VERSION ""

NS_ :

BS_:

BU_: INV BMS VCU

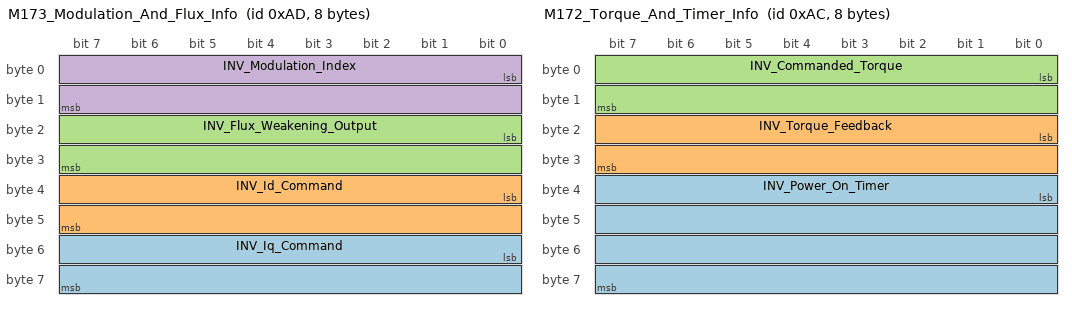
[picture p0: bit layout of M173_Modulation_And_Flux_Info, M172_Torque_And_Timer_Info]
BO_ 173 M173_Modulation_And_Flux_Info: 8 INV
 SG_ INV_Iq_Command : 48|16@1- (0.1,0) [-3276.8|3276.7] "current:A" Vector__XXX
 SG_ INV_Id_Command : 32|16@1- (0.1,0) [-3276.8|3276.7] "current:A" Vector__XXX
 SG_ INV_Flux_Weakening_Output : 16|16@1- (0.1,0) [-3276.8|3276.7] "current:A" Vector__XXX
 SG_ INV_Modulation_Index : 0|16@1- (0.0001,0) [-3.2768|3.2767] "" Vector__XXX

BO_ 172 M172_Torque_And_Timer_Info: 8 INV
 SG_ INV_Power_On_Timer : 32|32@1+ (0.003,0) [0|12884800] "time:second" Vector__XXX
 SG_ INV_Torque_Feedback : 16|16@1- (0.1,0) [-3276.8|3276.7] "torque:N.m" Vector__XXX
 SG_ INV_Commanded_Torque : 0|16@1- (0.1,0) [-3276.8|3276.7] "torque:N.m" Vector__XXX

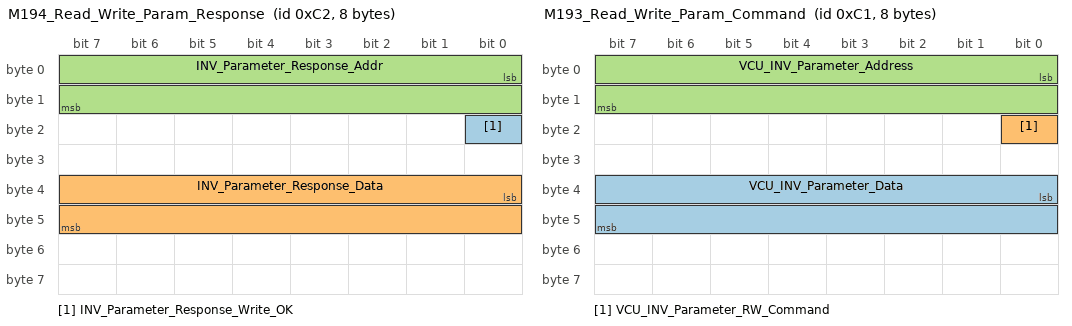
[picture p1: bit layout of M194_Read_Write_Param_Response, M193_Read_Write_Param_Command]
BO_ 194 M194_Read_Write_Param_Response: 8 INV
 SG_ INV_Parameter_Response_Write_OK : 16|1@1+ (1,0) [0|1] "" Vector__XXX
 SG_ INV_Parameter_Response_Data : 32|16@1- (1,0) [-32768|32767] "" Vector__XXX
 SG_ INV_Parameter_Response_Addr : 0|16@1+ (1,0) [0|65535] "" Vector__XXX

BO_ 193 M193_Read_Write_Param_Command: 8 VCU
 SG_ VCU_INV_Parameter_Data : 32|16@1- (1,0) [-32768|32767] "" Vector__XXX
 SG_ VCU_INV_Parameter_RW_Command : 16|1@1+ (1,0) [0|1] "" Vector__XXX
 SG_ VCU_INV_Parameter_Address : 0|16@1+ (1,0) [0|65535] "" Vector__XXX

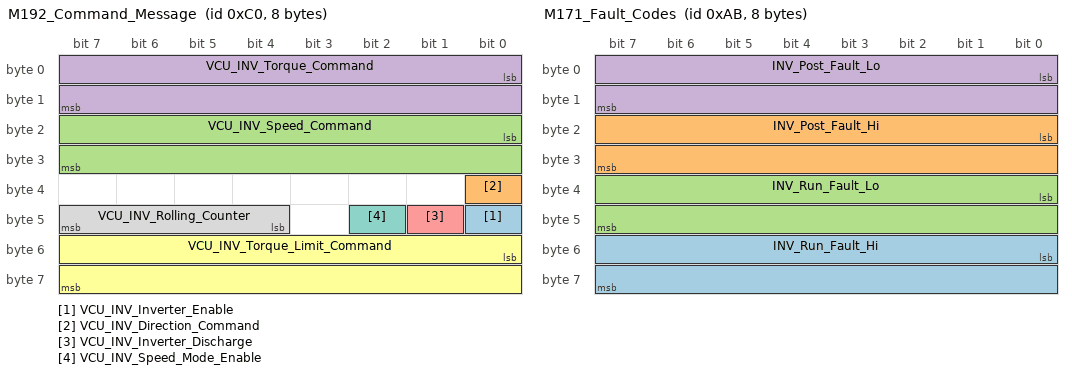
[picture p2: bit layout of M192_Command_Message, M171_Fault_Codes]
BO_ 192 M192_Command_Message: 8 VCU
 SG_ VCU_INV_Inverter_Enable : 40|1@1+ (1,0) [0|1] "" Vector__XXX
 SG_ VCU_INV_Direction_Command : 32|1@1+ (1,0) [0|1] "" Vector__XXX
 SG_ VCU_INV_Speed_Command : 16|16@1- (1,0) [-32768|32767] "angular_speed:rpm" Vector__XXX
 SG_ VCU_INV_Torque_Command : 0|16@1- (0.1,0) [-3276.8|3276.7] "torque:N.m" Vector__XXX
 SG_ VCU_INV_Inverter_Discharge : 41|1@1+ (1,0) [0|1] "" Vector__XXX
 SG_ VCU_INV_Torque_Limit_Command : 48|16@1- (0.1,0) [-3276.8|3276.7] "torque:N.m" Vector__XXX
 SG_ VCU_INV_Speed_Mode_Enable : 42|1@1+ (1,0) [0|1] "" Vector__XXX
 SG_ VCU_INV_Rolling_Counter : 44|4@1+ (1,0) [0|15] "" Vector__XXX

BO_ 171 M171_Fault_Codes: 8 INV
 SG_ INV_Run_Fault_Hi : 48|16@1+ (1,0) [0|65535] "" Vector__XXX
 SG_ INV_Post_Fault_Hi : 16|16@1+ (1,0) [0|65535] "" Vector__XXX
 SG_ INV_Run_Fault_Lo : 32|16@1+ (1,0) [0|65535] "" Vector__XXX
 SG_ INV_Post_Fault_Lo : 0|16@1+ (1,0) [0|65535] "" Vector__XXX

BO_ 170 M170_Internal_States: 8 INV
 SG_ INV_Direction_Command : 56|1@1+ (1,0) [0|1] "" Vector__XXX
 SG_ INV_Inverter_Enable_State : 48|1@1+ (1,0) [0|1] "" Vector__XXX
 SG_ INV_Relay_3_Status : 26|1@1+ (1,0) [0|1] "" Vector__XXX
 SG_ INV_Relay_4_Status : 27|1@1+ (1,0) [0|1] "" Vector__XXX
 SG_ INV_Relay_2_Status : 25|1@1+ (1,0) [0|1] "" Vector__XXX
 SG_ INV_Inverter_Run_Mode : 32|1@1+ (1,0) [0|1] "" Vector__XXX
 SG_ INV_Inverter_Command_Mode : 40|1@1+ (1,0) [0|1] "" Vector__XXX
 SG_ INV_Relay_1_Status : 24|1@1+ (1,0) [0|1] "" Vector__XXX
 SG_ INV_Inverter_State : 16|8@1+ (1,0) [0|255] "" Vector__XXX
 SG_ INV_VSM_State : 0|8@1+ (1,0) [0|15] "" Vector__XXX
 SG_ INV_Inverter_Enable_Lockout : 55|1@1+ (1,0) [0|1] "" Vector__XXX
 SG_ INV_Inverter_Discharge_State : 37|3@1+ (1,0) [0|7] "" Vector__XXX
 SG_ INV_Relay_5_Status : 28|1@1+ (1,0) [0|1] "" Vector__XXX
 SG_ INV_Relay_6_Status : 29|1@1+ (1,0) [0|1] "" Vector__XXX
 SG_ INV_BMS_Active : 57|1@1+ (1,0) [0|1] "" Vector__XXX
 SG_ INV_BMS_Torque_Limiting : 58|1@1+ (1,0) [0|1] "" Vector__XXX
 SG_ INV_PWM_Frequency : 8|8@1+ (1,0) [0|255] "" Vector__XXX
 SG_ INV_Limit_Max_Speed : 59|1@1+ (1,0) [0|1] "" Vector__XXX
 SG_ INV_Limit_Hot_Spot : 60|1@1+ (1,0) [0|1] "" Vector__XXX
 SG_ INV_Low_Speed_Limiting : 61|1@1+ (1,0) [0|1] "" Vector__XXX
 SG_ INV_Rolling_Counter : 44|4@1+ (1,0) [0|15] "" Vector__XXX
 SG_ INV_Limit_Coolant_Derating : 62|1@1+ (1,0) [0|1] "" Vector__XXX
 SG_ INV_Self_Sensing_Assist_Enable : 33|1@1+ (1,0) [0|1] "" Vector__XXX
 SG_ INV_Limit_Stall_Burst_Model : 63|1@1+ (1,0) [0|1] "" Vector__XXX
 SG_ INV_Burst_Model_Mode : 49|1@1+ (1,0) [0|1] "" Vector__XXX
 SG_ INV_Key_Switch_Start_Status : 54|1@1+ (1,0) [0|1] "" Vector__XXX

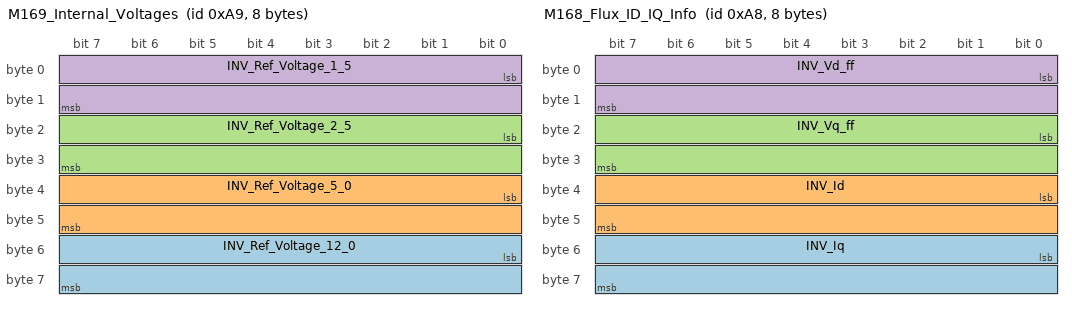
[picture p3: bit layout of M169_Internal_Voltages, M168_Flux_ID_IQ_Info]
BO_ 169 M169_Internal_Voltages: 8 INV
 SG_ INV_Ref_Voltage_12_0 : 48|16@1- (0.01,0) [-327.68|327.67] "voltage:V" Vector__XXX
 SG_ INV_Ref_Voltage_5_0 : 32|16@1- (0.01,0) [-327.68|327.67] "voltage:V" Vector__XXX
 SG_ INV_Ref_Voltage_2_5 : 16|16@1- (0.01,0) [-327.68|327.67] "voltage:V" Vector__XXX
 SG_ INV_Ref_Voltage_1_5 : 0|16@1- (0.01,0) [-327.68|327.67] "voltage:V" Vector__XXX

BO_ 168 M168_Flux_ID_IQ_Info: 8 INV
 SG_ INV_Iq : 48|16@1- (0.1,0) [-3276.8|3276.7] "current:A" Vector__XXX
 SG_ INV_Id : 32|16@1- (0.1,0) [-3276.8|3276.7] "current:A" Vector__XXX
 SG_ INV_Vq_ff : 16|16@1- (0.1,0) [-3276.7|3276.7] "voltage:V" Vector__XXX
 SG_ INV_Vd_ff : 0|16@1- (0.1,0) [-3276.7|3276.7] "voltage:V" Vector__XXX

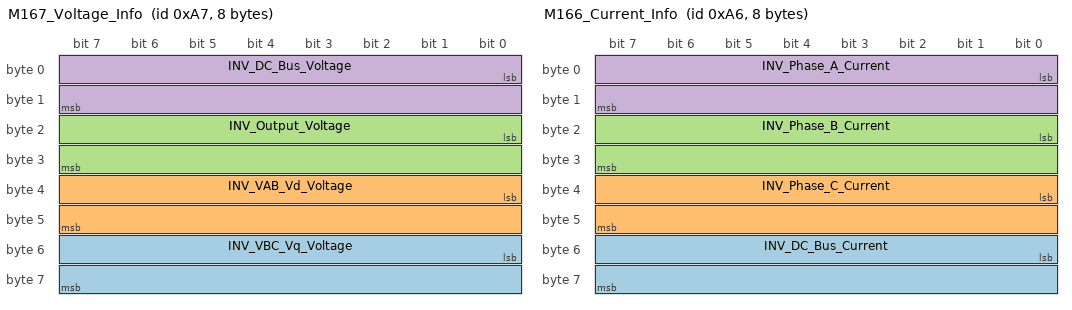
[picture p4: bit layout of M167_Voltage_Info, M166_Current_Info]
BO_ 167 M167_Voltage_Info: 8 INV
 SG_ INV_VBC_Vq_Voltage : 48|16@1- (0.1,0) [-3276.8|3276.7] "voltage:V" Vector__XXX
 SG_ INV_VAB_Vd_Voltage : 32|16@1- (0.1,0) [-3276.8|3276.7] "voltage:V" Vector__XXX
 SG_ INV_Output_Voltage : 16|16@1- (0.1,0) [-3276.8|3276.7] "voltage:V" Vector__XXX
 SG_ INV_DC_Bus_Voltage : 0|16@1- (0.1,0) [-3276.8|3276.7] "voltage:V" Vector__XXX

BO_ 166 M166_Current_Info: 8 INV
 SG_ INV_DC_Bus_Current : 48|16@1- (0.1,0) [-3276.8|3276.7] "current:A" Vector__XXX
 SG_ INV_Phase_C_Current : 32|16@1- (0.1,0) [-3276.8|3276.7] "current:A" Vector__XXX
 SG_ INV_Phase_B_Current : 16|16@1- (0.1,0) [-3276.8|3276.7] "current:A" Vector__XXX
 SG_ INV_Phase_A_Current : 0|16@1- (0.1,0) [-3276.8|3276.7] "current:A" Vector__XXX

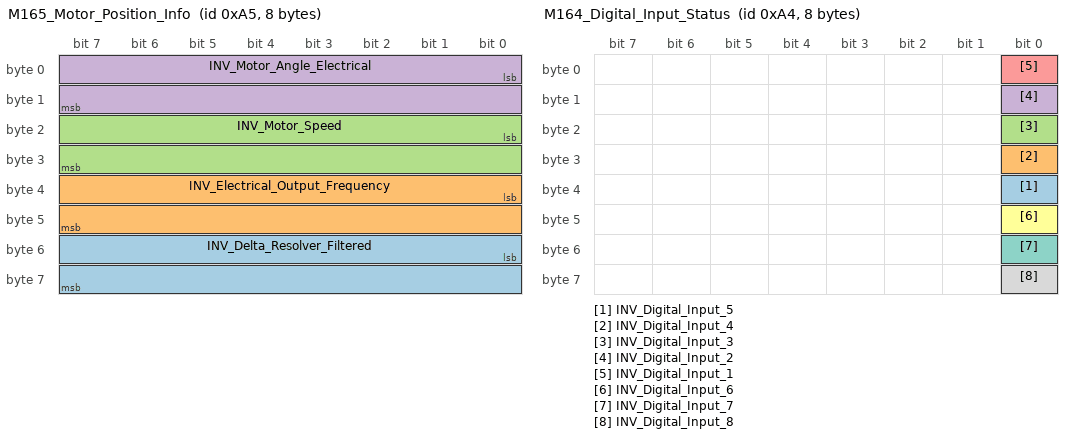
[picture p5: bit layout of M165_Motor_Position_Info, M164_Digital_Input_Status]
BO_ 165 M165_Motor_Position_Info: 8 INV
 SG_ INV_Delta_Resolver_Filtered : 48|16@1- (0.1,0) [-3276.8|3276.7] "angle:deg" Vector__XXX
 SG_ INV_Electrical_Output_Frequency : 32|16@1- (0.1,0) [-3276.8|3276.7] "frequency:Hz" Vector__XXX
 SG_ INV_Motor_Speed : 16|16@1- (1,0) [-32768|32767] "angular_speed:rpm" Vector__XXX
 SG_ INV_Motor_Angle_Electrical : 0|16@1+ (0.1,0) [0|6553.5] "angle:deg" Vector__XXX

BO_ 164 M164_Digital_Input_Status: 8 INV
 SG_ INV_Digital_Input_5 : 32|1@1+ (1,0) [0|1] "" Vector__XXX
 SG_ INV_Digital_Input_4 : 24|1@1+ (1,0) [0|1] "" Vector__XXX
 SG_ INV_Digital_Input_3 : 16|1@1+ (1,0) [0|1] "" Vector__XXX
 SG_ INV_Digital_Input_2 : 8|1@1+ (1,0) [0|1] "" Vector__XXX
 SG_ INV_Digital_Input_1 : 0|1@1+ (1,0) [0|1] "" Vector__XXX
 SG_ INV_Digital_Input_6 : 40|1@1+ (1,0) [0|1] "" Vector__XXX
 SG_ INV_Digital_Input_7 : 48|1@1+ (1,0) [0|1] "" Vector__XXX
 SG_ INV_Digital_Input_8 : 56|1@1+ (1,0) [0|1] "" Vector__XXX

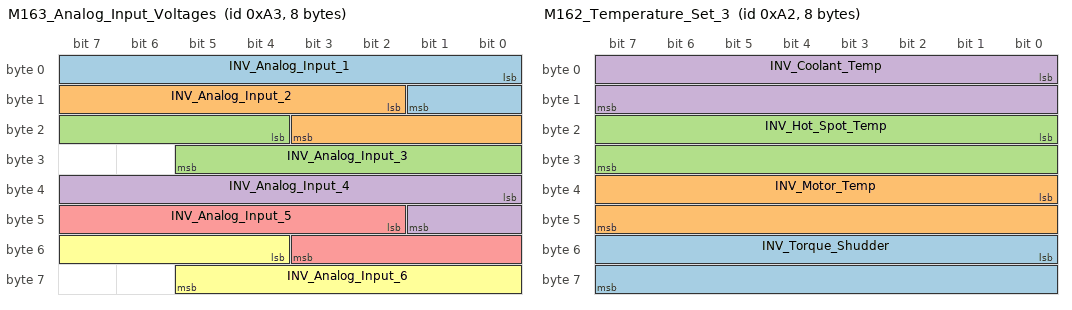
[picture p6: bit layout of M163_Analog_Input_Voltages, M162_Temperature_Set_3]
BO_ 163 M163_Analog_Input_Voltages: 8 INV
 SG_ INV_Analog_Input_1 : 0|10@1+ (0.01,0) [0|10.23] "voltage:V" Vector__XXX
 SG_ INV_Analog_Input_2 : 10|10@1+ (0.01,0) [0|10.23] "voltage:V" Vector__XXX
 SG_ INV_Analog_Input_3 : 20|10@1+ (0.01,0) [0|10.23] "voltage:V" Vector__XXX
 SG_ INV_Analog_Input_4 : 32|10@1+ (0.01,0) [0|10.23] "voltage:V" Vector__XXX
 SG_ INV_Analog_Input_5 : 42|10@1+ (0.01,0) [0|10.23] "voltage:V" Vector__XXX
 SG_ INV_Analog_Input_6 : 52|10@1+ (0.01,0) [0|10.23] "voltage:V" Vector__XXX

BO_ 162 M162_Temperature_Set_3: 8 INV
 SG_ INV_Torque_Shudder : 48|16@1- (0.1,0) [-3276.8|3276.7] "torque:N.m" Vector__XXX
 SG_ INV_Motor_Temp : 32|16@1- (0.1,0) [-3276.8|3276.7] "temperature:C" Vector__XXX
 SG_ INV_Hot_Spot_Temp : 16|16@1- (0.1,0) [-3276.8|3276.7] "temperature:C" Vector__XXX
 SG_ INV_Coolant_Temp : 0|16@1- (0.1,0) [-3276.8|3276.7] "temperature:C" Vector__XXX

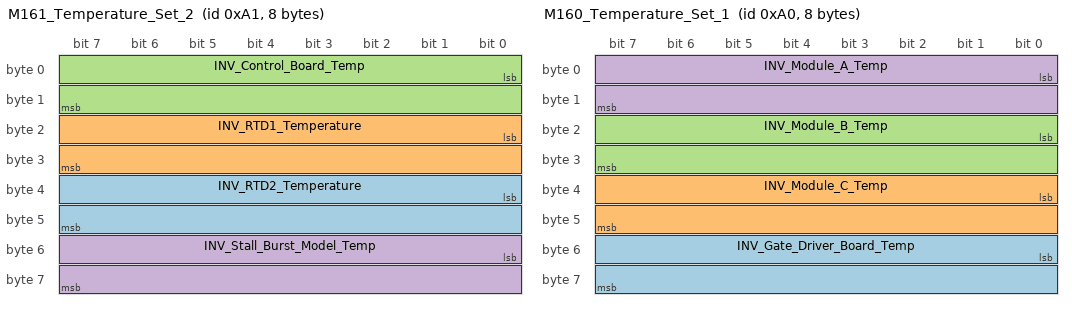
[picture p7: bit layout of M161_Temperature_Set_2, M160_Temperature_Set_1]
BO_ 161 M161_Temperature_Set_2: 8 INV
 SG_ INV_RTD2_Temperature : 32|16@1- (0.1,0) [-3276.8|3276.7] "temperature:C" Vector__XXX
 SG_ INV_RTD1_Temperature : 16|16@1- (0.1,0) [-3276.8|3276.7] "temperature:C" Vector__XXX
 SG_ INV_Control_Board_Temp : 0|16@1- (0.1,0) [-3276.8|3276.7] "temperature:C" Vector__XXX
 SG_ INV_Stall_Burst_Model_Temp : 48|16@1- (0.1,0) [-3276.8|3276.7] "temperature:C" Vector__XXX

BO_ 160 M160_Temperature_Set_1: 8 INV
 SG_ INV_Gate_Driver_Board_Temp : 48|16@1- (0.1,0) [-3276.8|3276.7] "temperature:C" Vector__XXX
 SG_ INV_Module_C_Temp : 32|16@1- (0.1,0) [-3276.8|3276.7] "temperature:C" Vector__XXX
 SG_ INV_Module_B_Temp : 16|16@1- (0.1,0) [-3276.8|3276.7] "temperature:C" Vector__XXX
 SG_ INV_Module_A_Temp : 0|16@1- (0.1,0) [-3276.8|3276.7] "temperature:C" Vector__XXX

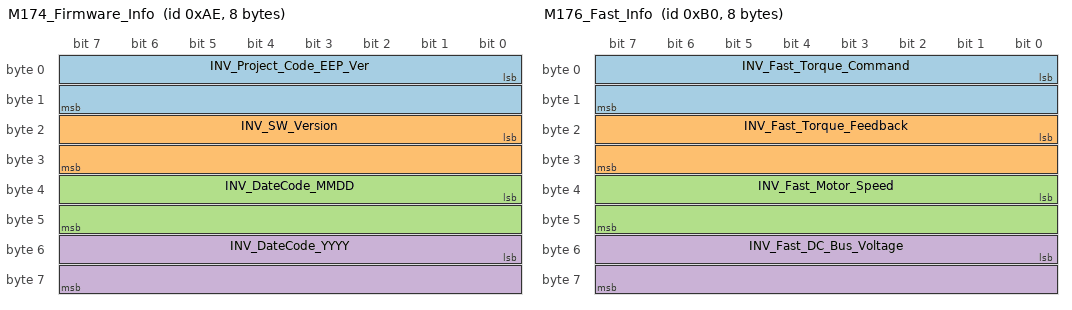
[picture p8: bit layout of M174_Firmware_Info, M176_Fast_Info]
BO_ 174 M174_Firmware_Info: 8 INV
 SG_ INV_Project_Code_EEP_Ver : 0|16@1+ (1,0) [0|65535] "" Vector__XXX
 SG_ INV_SW_Version : 16|16@1+ (1,0) [0|65535] "" Vector__XXX
 SG_ INV_DateCode_MMDD : 32|16@1+ (1,0) [0|65535] "" Vector__XXX
 SG_ INV_DateCode_YYYY : 48|16@1+ (1,0) [0|65535] "" Vector__XXX

BO_ 175 M175_Diag_Data_Message: 8 INV
 SG_ INV_Diag_Record : 0|8@1+ (1,0) [0|160] "" Vector__XXX
 SG_ INV_Diag_Segment M : 8|8@1+ (1,0) [0|5] "" Vector__XXX
 SG_ INV_Diag_Gamma_Resolver m0 : 16|16@1- (0.1,0) [0|360] "angle:deg" Vector__XXX
 SG_ INV_Diag_Gamma_Observer m0 : 32|16@1- (0.1,0) [0|360] "angle:deg" Vector__XXX
 SG_ INV_Diag_Sin_Used m0 : 48|16@1- (1,0) [-5|5] "voltage:V" Vector__XXX
 SG_ INV_Diag_Cos_Used m1 : 16|16@1- (1,0) [-5|5] "voltage:V" Vector__XXX
 SG_ INV_Diag_Ia m1 : 32|16@1- (0.1,0) [-2000|2000] "current:A" Vector__XXX
 SG_ INV_Diag_Ib m1 : 48|16@1- (0.1,0) [-2000|2000] "current:A" Vector__XXX
 SG_ INV_Diag_Ic m2 : 16|16@1- (0.1,0) [-2000|2000] "current:A" Vector__XXX
 SG_ INV_Diag_Vdc m2 : 32|16@1- (0.1,0) [0|1000] "voltage:V" Vector__XXX
 SG_ INV_Diag_Iq_cmd m2 : 48|16@1- (0.1,0) [-2000|2000] "current:A" Vector__XXX
 SG_ INV_Diag_Id_cmd m3 : 16|16@1- (0.1,0) [-2000|2000] "current:A" Vector__XXX
 SG_ INV_Diag_Mod_Index m3 : 32|16@1- (0.0001,0) [0|2] "" Vector__XXX
 SG_ INV_Diag_FW_Output m3 : 48|16@1- (0.1,0) [-2000|2000] "current:A" Vector__XXX
 SG_ INV_Diag_Vq_Cmd m4 : 16|16@1- (0.1,0) [-1000|1000] "voltage:V" Vector__XXX
 SG_ INV_Diag_Vd_Cmd m4 : 32|16@1- (0.1,0) [-1000|1000] "voltage:V" Vector__XXX
 SG_ INV_Diag_Vqs_Cmd m4 : 48|16@1- (0.1,0) [-1000|1000] "voltage:V" Vector__XXX
 SG_ INV_Diag_PWM_Freq m5 : 16|16@1+ (1,0) [0|24] "frequency:kHz" Vector__XXX
 SG_ INV_Diag_Run_Faults_Lo m5 : 32|16@1+ (1,0) [0|65535] "" Vector__XXX
 SG_ INV_Diag_Run_Faults_Hi m5 : 48|16@1+ (1,0) [0|65535] "" Vector__XXX

BO_ 514 BMS_Current_Limit: 8 BMS
 SG_ BMS_Max_Discharge_Current : 0|16@1+ (1,0) [0|1000] "current:A" Vector__XXX
 SG_ BMS_Max_Charge_Current : 16|16@1+ (1,0) [0|1000] "current:A" Vector__XXX

BO_ 176 M176_Fast_Info: 8 INV
 SG_ INV_Fast_Torque_Command : 0|16@1- (0.1,0) [-3276.8|32767.7] "torque:N.m" Vector__XXX
 SG_ INV_Fast_Torque_Feedback : 16|16@1- (0.1,0) [-3276.8|3276.7] "torque:N.m" Vector__XXX
 SG_ INV_Fast_Motor_Speed : 32|16@1- (1,0) [-32768|32767] "angular_speed:rpm" Vector__XXX
 SG_ INV_Fast_DC_Bus_Voltage : 48|16@1- (0.1,0) [-3276.8|3276.7] "voltage:V" Vector__XXX

BO_ 177 M177_Torque_Capability: 8 INV
 SG_ INV_Torque_Capability : 0|16@1+ (0.1,0) [0|6553.6] "torque:N.m" Vector__XXX

CM_ SG_ 173 INV_Iq_Command "The commanded Q-axis current";
CM_ SG_ 173 INV_Id_Command "The commanded D-axis current";
CM_ SG_ 173 INV_Flux_Weakening_Output "This is the current output of the flux regulator.";
CM_ SG_ 173 INV_Modulation_Index "This is the modulation index. The scale factor is x100. To get the actual modulation index divide the value by 100.";
CM_ SG_ 172 INV_Power_On_Timer "Updated every 3 msec. This will roll over in approximately 150 days!";
CM_ SG_ 172 INV_Torque_Feedback "Estimated motor torque feedback";
CM_ SG_ 172 INV_Commanded_Torque "The commanded Torque";
CM_ BO_ 194 "To write a parameter use message 0x0C1 with byte #2 set to 1 (write). 
To read a parameter use message 0x0C1 with byte #2 to set 0 (read). ";
CM_ SG_ 194 INV_Parameter_Response_Write_OK "0=Write failure, 1=Success";
CM_ SG_ 194 INV_Parameter_Response_Data "Data from parameter message.  All data is 16 bits and is contained in bytes 4 and 5. Bytes 6 and 7 should be ignored.";
CM_ SG_ 194 INV_Parameter_Response_Addr "Address of parameter response message data.";
CM_ BO_ 193 "To write a parameter use message 0x0C1 with byte #2 set to 1 (write). 
To read a parameter use message 0x0C1 with byte #2 to set 0 (read). ";
CM_ SG_ 193 VCU_INV_Parameter_Data "Data to be written.  All data is 16 bits and is contained in bytes 4 and 5.";
CM_ SG_ 193 VCU_INV_Parameter_RW_Command "0=Read, 1=Write";
CM_ SG_ 193 VCU_INV_Parameter_Address "Address of parameter to be written or read.";
CM_ BO_ 192 "The command message is used to transmit data to the controller. This message is sent from a user supplied external controller to the PMxxx controller.";
CM_ SG_ 192 VCU_INV_Inverter_Enable "0=Inverter OFF, 1 = Inverter ON";
CM_ SG_ 192 VCU_INV_Direction_Command "0=Reverse, 1=Forward.  Forward is positive motor speed.";
CM_ SG_ 192 VCU_INV_Speed_Command "Speed command used when in speed mode";
CM_ SG_ 192 VCU_INV_Torque_Command "Torque command when in torque mode";
CM_ SG_ 192 VCU_INV_Inverter_Discharge "0=Discharge Disable,1=Discharge Enable";
CM_ SG_ 192 VCU_INV_Torque_Limit_Command "Torque Limit, set to 0 to keep default";
CM_ SG_ 192 VCU_INV_Speed_Mode_Enable "0 = No change to mode, 1 = change to speed mode from torque mode";
CM_ SG_ 192 VCU_INV_Rolling_Counter "Rolling Counter sent to inverter.  If used increment count with each message sent.  Otherwise can be set to 0.";
CM_ SG_ 171 INV_Run_Fault_Hi "Each bit represents a fault. Please refer to PM100 Users Manual for details.";
CM_ SG_ 171 INV_Post_Fault_Hi "Each bit represents a fault. Please refer to PM100 Users Manual for details.";
CM_ SG_ 171 INV_Run_Fault_Lo "Each bit represents a fault. Please refer to PM100 Users Manual for details.";
CM_ SG_ 171 INV_Post_Fault_Lo "Each bit represents a fault. Please refer to PM100 Users Manual for details.";
CM_ SG_ 170 INV_Direction_Command "1 = Forward
0 = 'Reverse' if inverter enabled  & 'Stopped' if inverter is disabled";
CM_ SG_ 170 INV_Inverter_Enable_State "0=Inverter Disabled, 
1=Inverter Enabled";
CM_ SG_ 170 INV_Relay_3_Status "0=OFF, 1=ON";
CM_ SG_ 170 INV_Relay_4_Status "0=OFF, 1=ON";
CM_ SG_ 170 INV_Relay_2_Status "0=OFF, 1=ON";
CM_ SG_ 170 INV_Inverter_Run_Mode "0=Torque Mode, 1=Speed Mode";
CM_ SG_ 170 INV_Inverter_Command_Mode "0=CAN mode, 1=VSM mode";
CM_ SG_ 170 INV_Relay_1_Status "0=OFF, 1=ON";
CM_ SG_ 170 INV_Inverter_State "Different states for the inverter state machine";
CM_ SG_ 170 INV_VSM_State "Different states for the vehicle state machine";
CM_ SG_ 170 INV_Inverter_Enable_Lockout "0=Lockout Disabled, 1=Lockout Enabled";
CM_ SG_ 170 INV_Inverter_Discharge_State "0 = Disabled, 1 = Enabled, 2 = Speed Check, 3 = Active, 4 = Complete, 5 = Error, 6 = Override, 7 = Timeout";
CM_ SG_ 170 INV_Relay_5_Status "0=OFF, 1=ON";
CM_ SG_ 170 INV_Relay_6_Status "0=OFF, 1=ON";
CM_ SG_ 170 INV_BMS_Active "0 = BMS Not Active, 1 = BMS Active";
CM_ SG_ 170 INV_BMS_Torque_Limiting "0 = Not Limiting, 1 = Limiting";
CM_ SG_ 170 INV_PWM_Frequency "The current active PWM frequency";
CM_ SG_ 170 INV_Limit_Max_Speed "Indicates that torque is being modified to limit the speed.";
CM_ SG_ 170 INV_Limit_Hot_Spot "Indicates that torque is being limited to limit the hot spot temp";
CM_ SG_ 170 INV_Low_Speed_Limiting "Indicates that motor current is being limited due to low motor electrical frequency.";
CM_ SG_ 170 INV_Rolling_Counter "Rolling Counter value";
CM_ SG_ 170 INV_Limit_Coolant_Derating "0 = Not limiting, 1 = Limiting";
CM_ SG_ 170 INV_Self_Sensing_Assist_Enable "1 = Self Sensing Assist Enabled, 0 = Self Sensing Assist Disabled";
CM_ SG_ 170 INV_Limit_Stall_Burst_Model "0 = Not limiting, 1 = Limiting";
CM_ SG_ 170 INV_Burst_Model_Mode "0 = Stall, 1 = High Speed";
CM_ SG_ 170 INV_Key_Switch_Start_Status "0 = OFF, 1 = ON";
CM_ SG_ 169 INV_Ref_Voltage_12_0 "12V Input Voltage";
CM_ SG_ 169 INV_Ref_Voltage_5_0 "Transducer voltage";
CM_ SG_ 169 INV_Ref_Voltage_2_5 "Internal reference voltage";
CM_ SG_ 169 INV_Ref_Voltage_1_5 "Internal reference voltage";
CM_ SG_ 168 INV_Iq "The measured Iq current";
CM_ SG_ 168 INV_Id "The measured Id current";
CM_ SG_ 168 INV_Vq_ff "The q-axis voltage feedforward";
CM_ SG_ 168 INV_Vd_ff "The d-axis voltage feedforward";
CM_ SG_ 167 INV_VBC_Vq_Voltage "Measured value of the voltage between Phase B and Phase C";
CM_ SG_ 167 INV_VAB_Vd_Voltage "Measured value of the voltage betwen phase A and Phase B";
CM_ SG_ 167 INV_Output_Voltage "The calculated value of the output voltage, in peak line-neutral volts";
CM_ SG_ 167 INV_DC_Bus_Voltage "The actual measured value of the DC bus voltage";
CM_ SG_ 166 INV_DC_Bus_Current "The Calculated DC Bus Current";
CM_ SG_ 166 INV_Phase_C_Current "The measured value of Phase C current";
CM_ SG_ 166 INV_Phase_B_Current "The measured value of Phase B current";
CM_ SG_ 166 INV_Phase_A_Current "The measured value of Phase A current";
CM_ SG_ 165 INV_Delta_Resolver_Filtered "Used in calibration of resolver angle adjustment.";
CM_ SG_ 165 INV_Electrical_Output_Frequency "The actual electrical frequency of the inverter";
CM_ SG_ 165 INV_Motor_Speed "The measured speed of the motor";
CM_ SG_ 165 INV_Motor_Angle_Electrical "The Electrical Angle of the motor as read by the encoder or resolver";
CM_ SG_ 164 INV_Digital_Input_5 "Status of Digital Input #5";
CM_ SG_ 164 INV_Digital_Input_4 "Status of Digital Input #4";
CM_ SG_ 164 INV_Digital_Input_3 "Status of Digital Input #3";
CM_ SG_ 164 INV_Digital_Input_2 "Status of Digital Input #2";
CM_ SG_ 164 INV_Digital_Input_1 "Status of Digital Input #1";
CM_ SG_ 164 INV_Digital_Input_6 "Status of Digital Input #6";
CM_ SG_ 164 INV_Digital_Input_7 "Status of Digital Input #7";
CM_ SG_ 164 INV_Digital_Input_8 "Status of Digital Input #8";
CM_ SG_ 163 INV_Analog_Input_1 "Voltage on Analog Input #1";
CM_ SG_ 163 INV_Analog_Input_2 "Voltage on Analog Input #2";
CM_ SG_ 163 INV_Analog_Input_3 "Voltage on Analog Input #3";
CM_ SG_ 163 INV_Analog_Input_4 "Voltage on Analog Input #4";
CM_ SG_ 163 INV_Analog_Input_5 "Voltage on Analog Input #5";
CM_ SG_ 163 INV_Analog_Input_6 "Voltage on Analog Input #6";
CM_ SG_ 162 INV_Torque_Shudder "Shudder compensation value of torque";
CM_ SG_ 162 INV_Motor_Temp "Motor Temperature Sensor";
CM_ SG_ 162 INV_Hot_Spot_Temp "Estimated inverter hot spot temperature";
CM_ SG_ 162 INV_Coolant_Temp "Estimated Coolant Temperature";
CM_ SG_ 161 INV_RTD2_Temperature "RTD input 2 (PT1000) Temperature";
CM_ SG_ 161 INV_RTD1_Temperature "RTD input 1 (PT1000) Temperature";
CM_ SG_ 161 INV_Control_Board_Temp "Control Board Temperature";
CM_ SG_ 161 INV_Stall_Burst_Model_Temp "Hottest temperature estimated from the stall burst thermal model feature";
CM_ SG_ 160 INV_Gate_Driver_Board_Temp "Gate Driver Board Temperature";
CM_ SG_ 160 INV_Module_C_Temp "IGBT Module C Temperature";
CM_ SG_ 160 INV_Module_B_Temp "IGBT Module B Temperature";
CM_ SG_ 160 INV_Module_A_Temp "IGBT Module A Temperature";
CM_ BO_ 514 "Sent by BMS";
CM_ SG_ 514 BMS_Max_Discharge_Current "Maximum discharge current from BMS";
CM_ SG_ 514 BMS_Max_Charge_Current "Maximum charge current from BMS";
CM_ BO_ 176 "To enable fast message set CAN ACTIVE MSGS HI WORD to 0xFFFE.  Setting to default value of 0xFFFF will disable the fast message.";
CM_ SG_ 176 INV_Fast_Torque_Command "The commanded torque";
CM_ SG_ 176 INV_Fast_Torque_Feedback "The estimated torque";
CM_ SG_ 176 INV_Fast_Motor_Speed "Motor speed";
CM_ SG_ 176 INV_Fast_DC_Bus_Voltage "DC Bus Voltage";
CM_ SG_ 177 INV_Torque_Capability "The torque capability of the inverter given the current operating point.";
BA_DEF_ BO_  "GenMsgCycleTime" INT 0 100000;
BA_DEF_  "BusType" STRING ;
BA_DEF_DEF_  "GenMsgCycleTime" 0;
BA_DEF_DEF_  "BusType" "CAN";
BA_ "GenMsgCycleTime" BO_ 172 10;
BA_ "GenMsgCycleTime" BO_ 192 10;
BA_ "GenMsgCycleTime" BO_ 171 100;
BA_ "GenMsgCycleTime" BO_ 170 100;
BA_ "GenMsgCycleTime" BO_ 169 100;
BA_ "GenMsgCycleTime" BO_ 168 10;
BA_ "GenMsgCycleTime" BO_ 167 10;
BA_ "GenMsgCycleTime" BO_ 166 10;
BA_ "GenMsgCycleTime" BO_ 165 10;
BA_ "GenMsgCycleTime" BO_ 164 10;
BA_ "GenMsgCycleTime" BO_ 163 10;
BA_ "GenMsgCycleTime" BO_ 162 100;
BA_ "GenMsgCycleTime" BO_ 161 100;
BA_ "GenMsgCycleTime" BO_ 160 100;
BA_ "GenMsgCycleTime" BO_ 176 3;
BA_ "GenMsgCycleTime" BO_ 177 10;
VAL_ 192 VCU_INV_Inverter_Enable 0 "Turn the inverter OFF" 1 "Turn the Inverter ON" ;
VAL_ 192 VCU_INV_Direction_Command 0 "CW" 1 "CCW" ;
VAL_ 192 VCU_INV_Inverter_Discharge 0 "Discharge Disable" 1 "Discharge Enable (if EEPROM parameter is set)" ;
VAL_ 170 INV_Inverter_State 0 "Power up" 1 "Stop" 2 "Open Loop" 3 "Closed Loop" 4 "Internal State" 5 "Internal State" 6 "Internal State" 7 "Internal State" 8 "Idle Run" 9 "Idle Stop" 10 "Internal State" 11 "Intern State" 12 "Internal State" ;
VAL_ 170 INV_VSM_State 0 "VSM Start State" 1 "Pre-Charge Init state" 2 "pre-charge active state" 3 "pre-charge complete state" 4 "VSM wait state" 5 "VSM ready state" 6 "Motor Running State" 7 "blink fault code state" 14 "Shutdown state for Key Switch Mode 1" 15 "Reset the inverter" ;
VAL_ 170 INV_Inverter_Discharge_State 0 "Disabled" 1 "Enabled" 2 "Speed Check" 3 "Active" 4 "Complete" 5 "Error" 6 "Override" 7 "Timeout" ;
VAL_ 170 INV_Limit_Stall_Burst_Model 0 "Not Limiting" 1 "Limiting" ;
VAL_ 170 INV_Burst_Model_Mode 0 "Stall" 1 "High Speed" ;

BO_ 1224 LF_IRTS_Brake_5: 2 Vector__XXX
 SG_ LF_Sensor_Temp : 7|16@0+ (0.1,-100) [-100|6453.5] "C" Vector__XXX

BO_ 1229 RF_IRTS_Brake_5: 2 Vector__XXX
 SG_ RF_Sensor_Temp : 7|16@0+ (0.1,-100) [-100|6453.5] "C" Vector__XXX

BO_ 1239 RR_IRTS_Brake_5: 2 Vector__XXX
 SG_ RR_Sensor_Temp : 7|16@0+ (0.1,-100) [-100|6453.5] "C" Vector__XXX

BO_ 1234 LR_IRTS_Brake_5: 2 Vector__XXX
 SG_ LR_Sensor_Temp : 7|16@0+ (0.1,-100) [-100|6453.5] "C" Vector__XXX

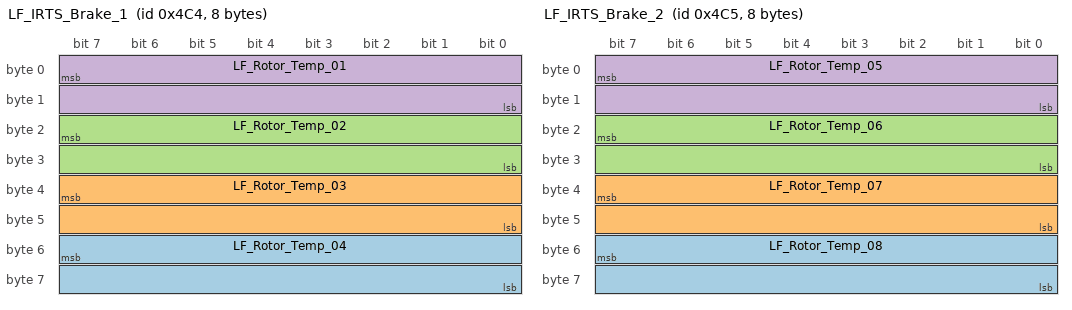
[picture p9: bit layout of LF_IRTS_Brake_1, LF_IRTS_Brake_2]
BO_ 1220 LF_IRTS_Brake_1: 8 Vector__XXX
 SG_ LF_Rotor_Temp_04 : 55|16@0+ (0.1,-100) [-100|6453.5] "C" Vector__XXX
 SG_ LF_Rotor_Temp_03 : 39|16@0+ (0.1,-100) [-100|6453.5] "C" Vector__XXX
 SG_ LF_Rotor_Temp_02 : 23|16@0+ (0.1,-100) [-100|6453.5] "C" Vector__XXX
 SG_ LF_Rotor_Temp_01 : 7|16@0+ (0.1,-100) [-100|6453.5] "C" Vector__XXX

BO_ 1221 LF_IRTS_Brake_2: 8 Vector__XXX
 SG_ LF_Rotor_Temp_08 : 55|16@0+ (0.1,-100) [-100|6453.5] "C" Vector__XXX
 SG_ LF_Rotor_Temp_07 : 39|16@0+ (0.1,-100) [-100|6453.5] "C" Vector__XXX
 SG_ LF_Rotor_Temp_06 : 23|16@0+ (0.1,-100) [-100|6453.5] "C" Vector__XXX
 SG_ LF_Rotor_Temp_05 : 7|16@0+ (0.1,-100) [-100|6453.5] "C" Vector__XXX

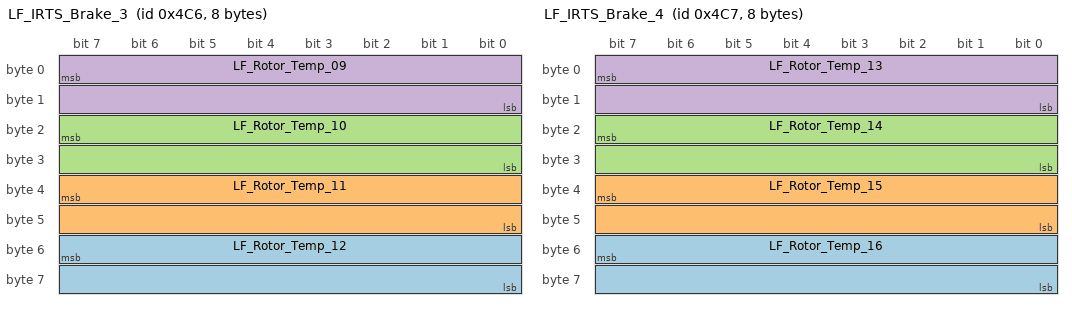
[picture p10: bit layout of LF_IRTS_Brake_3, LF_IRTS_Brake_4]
BO_ 1222 LF_IRTS_Brake_3: 8 Vector__XXX
 SG_ LF_Rotor_Temp_12 : 55|16@0+ (0.1,-100) [-100|6453.5] "C" Vector__XXX
 SG_ LF_Rotor_Temp_11 : 39|16@0+ (0.1,-100) [-100|6453.5] "C" Vector__XXX
 SG_ LF_Rotor_Temp_10 : 23|16@0+ (0.1,-100) [-100|6453.5] "C" Vector__XXX
 SG_ LF_Rotor_Temp_09 : 7|16@0+ (0.1,-100) [-100|6453.5] "C" Vector__XXX

BO_ 1223 LF_IRTS_Brake_4: 8 Vector__XXX
 SG_ LF_Rotor_Temp_16 : 55|16@0+ (0.1,-100) [-100|6453.5] "C" Vector__XXX
 SG_ LF_Rotor_Temp_15 : 39|16@0+ (0.1,-100) [-100|6453.5] "C" Vector__XXX
 SG_ LF_Rotor_Temp_14 : 23|16@0+ (0.1,-100) [-100|6453.5] "C" Vector__XXX
 SG_ LF_Rotor_Temp_13 : 7|16@0+ (0.1,-100) [-100|6453.5] "C" Vector__XXX

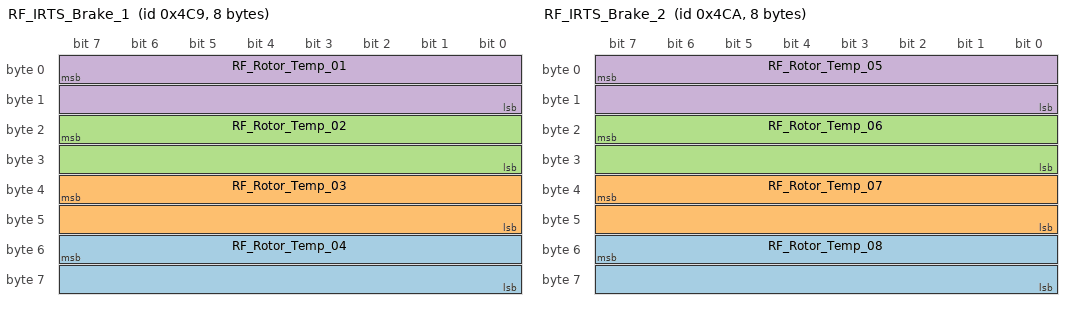
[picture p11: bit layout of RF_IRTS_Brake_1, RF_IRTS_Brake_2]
BO_ 1225 RF_IRTS_Brake_1: 8 Vector__XXX
 SG_ RF_Rotor_Temp_04 : 55|16@0+ (0.1,-100) [-100|6453.5] "C" Vector__XXX
 SG_ RF_Rotor_Temp_03 : 39|16@0+ (0.1,-100) [-100|6453.5] "C" Vector__XXX
 SG_ RF_Rotor_Temp_02 : 23|16@0+ (0.1,-100) [-100|6453.5] "C" Vector__XXX
 SG_ RF_Rotor_Temp_01 : 7|16@0+ (0.1,-100) [-100|6453.5] "C" Vector__XXX

BO_ 1226 RF_IRTS_Brake_2: 8 Vector__XXX
 SG_ RF_Rotor_Temp_08 : 55|16@0+ (0.1,-100) [-100|6453.5] "C" Vector__XXX
 SG_ RF_Rotor_Temp_07 : 39|16@0+ (0.1,-100) [-100|6453.5] "C" Vector__XXX
 SG_ RF_Rotor_Temp_06 : 23|16@0+ (0.1,-100) [-100|6453.5] "C" Vector__XXX
 SG_ RF_Rotor_Temp_05 : 7|16@0+ (0.1,-100) [-100|6453.5] "C" Vector__XXX

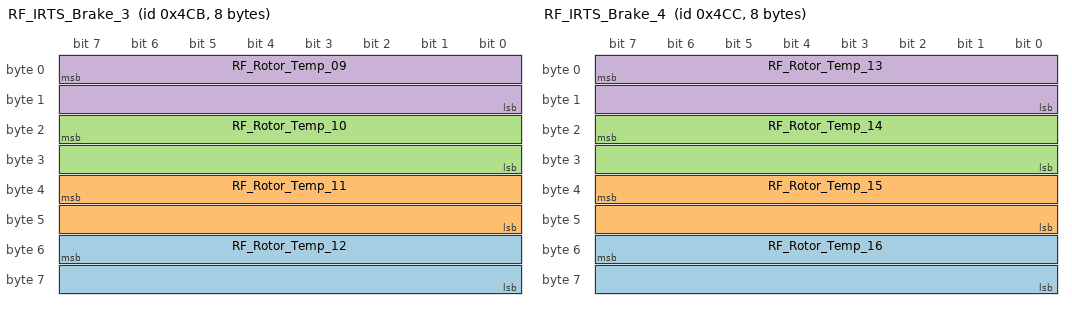
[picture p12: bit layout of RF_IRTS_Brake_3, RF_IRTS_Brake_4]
BO_ 1227 RF_IRTS_Brake_3: 8 Vector__XXX
 SG_ RF_Rotor_Temp_12 : 55|16@0+ (0.1,-100) [-100|6453.5] "C" Vector__XXX
 SG_ RF_Rotor_Temp_11 : 39|16@0+ (0.1,-100) [-100|6453.5] "C" Vector__XXX
 SG_ RF_Rotor_Temp_10 : 23|16@0+ (0.1,-100) [-100|6453.5] "C" Vector__XXX
 SG_ RF_Rotor_Temp_09 : 7|16@0+ (0.1,-100) [-100|6453.5] "C" Vector__XXX

BO_ 1228 RF_IRTS_Brake_4: 8 Vector__XXX
 SG_ RF_Rotor_Temp_16 : 55|16@0+ (0.1,-100) [-100|6453.5] "C" Vector__XXX
 SG_ RF_Rotor_Temp_15 : 39|16@0+ (0.1,-100) [-100|6453.5] "C" Vector__XXX
 SG_ RF_Rotor_Temp_14 : 23|16@0+ (0.1,-100) [-100|6453.5] "C" Vector__XXX
 SG_ RF_Rotor_Temp_13 : 7|16@0+ (0.1,-100) [-100|6453.5] "C" Vector__XXX

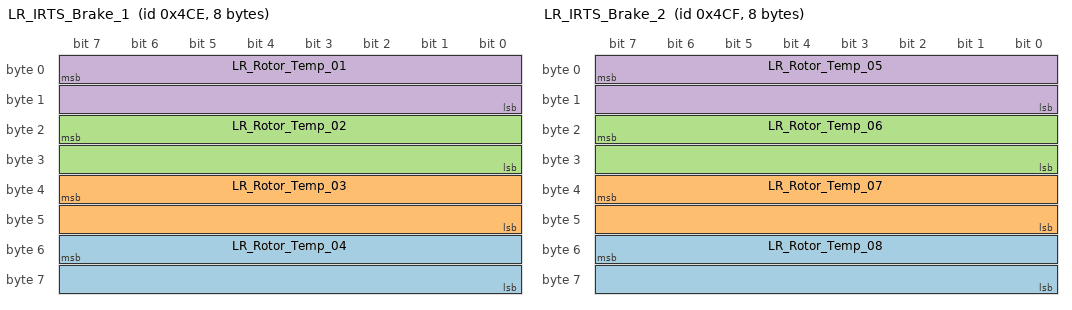
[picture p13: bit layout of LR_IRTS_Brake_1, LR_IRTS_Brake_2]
BO_ 1230 LR_IRTS_Brake_1: 8 Vector__XXX
 SG_ LR_Rotor_Temp_04 : 55|16@0+ (0.1,-100) [-100|6453.5] "C" Vector__XXX
 SG_ LR_Rotor_Temp_03 : 39|16@0+ (0.1,-100) [-100|6453.5] "C" Vector__XXX
 SG_ LR_Rotor_Temp_02 : 23|16@0+ (0.1,-100) [-100|6453.5] "C" Vector__XXX
 SG_ LR_Rotor_Temp_01 : 7|16@0+ (0.1,-100) [-100|6453.5] "C" Vector__XXX

BO_ 1231 LR_IRTS_Brake_2: 8 Vector__XXX
 SG_ LR_Rotor_Temp_08 : 55|16@0+ (0.1,-100) [-100|6453.5] "C" Vector__XXX
 SG_ LR_Rotor_Temp_07 : 39|16@0+ (0.1,-100) [-100|6453.5] "C" Vector__XXX
 SG_ LR_Rotor_Temp_06 : 23|16@0+ (0.1,-100) [-100|6453.5] "C" Vector__XXX
 SG_ LR_Rotor_Temp_05 : 7|16@0+ (0.1,-100) [-100|6453.5] "C" Vector__XXX

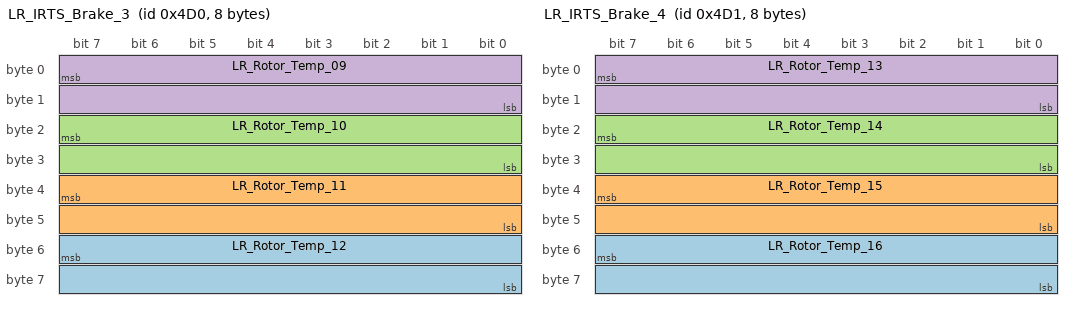
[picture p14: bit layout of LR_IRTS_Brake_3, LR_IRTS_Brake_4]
BO_ 1232 LR_IRTS_Brake_3: 8 Vector__XXX
 SG_ LR_Rotor_Temp_12 : 55|16@0+ (0.1,-100) [-100|6453.5] "C" Vector__XXX
 SG_ LR_Rotor_Temp_11 : 39|16@0+ (0.1,-100) [-100|6453.5] "C" Vector__XXX
 SG_ LR_Rotor_Temp_10 : 23|16@0+ (0.1,-100) [-100|6453.5] "C" Vector__XXX
 SG_ LR_Rotor_Temp_09 : 7|16@0+ (0.1,-100) [-100|6453.5] "C" Vector__XXX

BO_ 1233 LR_IRTS_Brake_4: 8 Vector__XXX
 SG_ LR_Rotor_Temp_16 : 55|16@0+ (0.1,-100) [-100|6453.5] "C" Vector__XXX
 SG_ LR_Rotor_Temp_15 : 39|16@0+ (0.1,-100) [-100|6453.5] "C" Vector__XXX
 SG_ LR_Rotor_Temp_14 : 23|16@0+ (0.1,-100) [-100|6453.5] "C" Vector__XXX
 SG_ LR_Rotor_Temp_13 : 7|16@0+ (0.1,-100) [-100|6453.5] "C" Vector__XXX

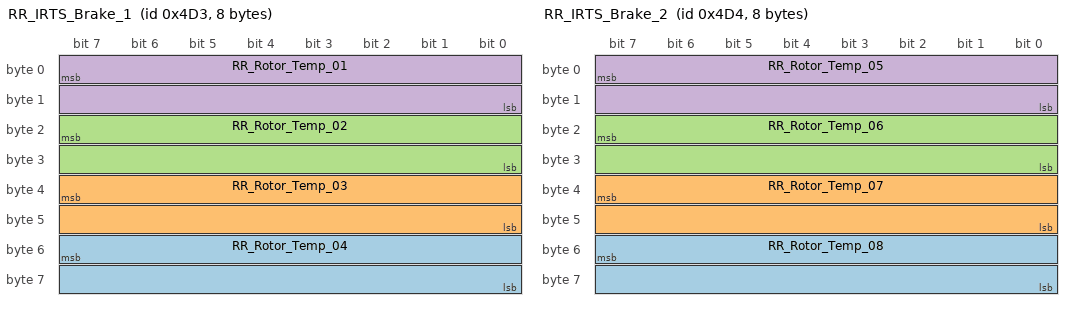
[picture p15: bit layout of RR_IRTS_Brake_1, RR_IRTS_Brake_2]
BO_ 1235 RR_IRTS_Brake_1: 8 Vector__XXX
 SG_ RR_Rotor_Temp_04 : 55|16@0+ (0.1,-100) [-100|6453.5] "C" Vector__XXX
 SG_ RR_Rotor_Temp_03 : 39|16@0+ (0.1,-100) [-100|6453.5] "C" Vector__XXX
 SG_ RR_Rotor_Temp_02 : 23|16@0+ (0.1,-100) [-100|6453.5] "C" Vector__XXX
 SG_ RR_Rotor_Temp_01 : 7|16@0+ (0.1,-100) [-100|6453.5] "C" Vector__XXX

BO_ 1236 RR_IRTS_Brake_2: 8 Vector__XXX
 SG_ RR_Rotor_Temp_08 : 55|16@0+ (0.1,-100) [-100|6453.5] "C" Vector__XXX
 SG_ RR_Rotor_Temp_07 : 39|16@0+ (0.1,-100) [-100|6453.5] "C" Vector__XXX
 SG_ RR_Rotor_Temp_06 : 23|16@0+ (0.1,-100) [-100|6453.5] "C" Vector__XXX
 SG_ RR_Rotor_Temp_05 : 7|16@0+ (0.1,-100) [-100|6453.5] "C" Vector__XXX

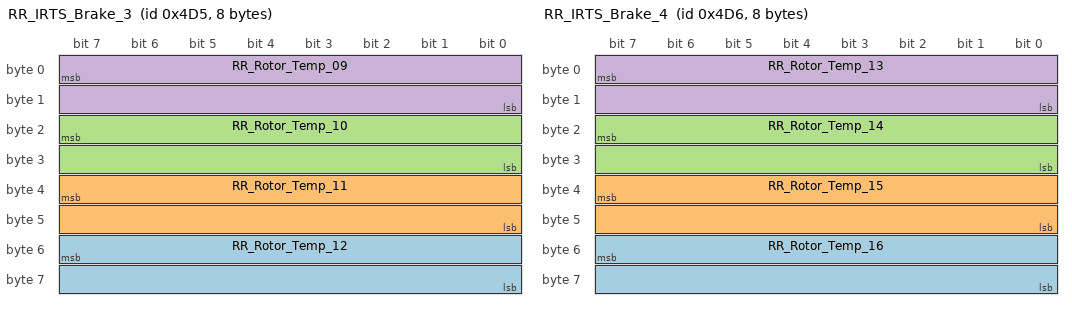
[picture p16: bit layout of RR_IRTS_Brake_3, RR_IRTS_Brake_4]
BO_ 1237 RR_IRTS_Brake_3: 8 Vector__XXX
 SG_ RR_Rotor_Temp_12 : 55|16@0+ (0.1,-100) [-100|6453.5] "C" Vector__XXX
 SG_ RR_Rotor_Temp_11 : 39|16@0+ (0.1,-100) [-100|6453.5] "C" Vector__XXX
 SG_ RR_Rotor_Temp_10 : 23|16@0+ (0.1,-100) [-100|6453.5] "C" Vector__XXX
 SG_ RR_Rotor_Temp_09 : 7|16@0+ (0.1,-100) [-100|6453.5] "C" Vector__XXX

BO_ 1238 RR_IRTS_Brake_4: 8 Vector__XXX
 SG_ RR_Rotor_Temp_16 : 55|16@0+ (0.1,-100) [-100|6453.5] "C" Vector__XXX
 SG_ RR_Rotor_Temp_15 : 39|16@0+ (0.1,-100) [-100|6453.5] "C" Vector__XXX
 SG_ RR_Rotor_Temp_14 : 23|16@0+ (0.1,-100) [-100|6453.5] "C" Vector__XXX
 SG_ RR_Rotor_Temp_13 : 7|16@0+ (0.1,-100) [-100|6453.5] "C" Vector__XXX

BO_ 256 Status: 8 Vector__XXX

BO_ 257 Faults: 8 Vector__XXX

BO_ 258 Dashboard: 8 Vector__XXX

BO_ 259 Temp1: 8 Vector__XXX
 SG_ Temp1 : 0|8@0+ (1,0) [0|120] "C" Vector__XXX
 SG_ Temp2 : 8|8@0+ (1,0) [0|120] "C" Vector__XXX
 SG_ Temp3 : 16|8@0+ (1,0) [0|120] "C" Vector__XXX
 SG_ Temp4 : 24|8@0+ (1,0) [0|120] "C" Vector__XXX
 SG_ Temp5 : 32|8@0+ (1,0) [0|120] "C" Vector__XXX
 SG_ Temp6 : 40|8@0+ (1,0) [0|120] "C" Vector__XXX
 SG_ Temp7 : 48|8@0+ (1,0) [0|120] "C" Vector__XXX
 SG_ Temp8 : 56|8@0+ (1,0) [0|120] "C" Vector__XXX

BO_ 260 Temp2: 8 Vector__XXX
 SG_ Temp9 : 0|8@0+ (1,0) [0|120] "C" Vector__XXX
 SG_ Temp10 : 8|8@0+ (1,0) [0|120] "C" Vector__XXX
 SG_ Temp11 : 16|8@0+ (1,0) [0|120] "C" Vector__XXX
 SG_ Temp12 : 24|8@0+ (1,0) [0|120] "C" Vector__XXX
 SG_ Temp13 : 32|8@0+ (1,0) [0|120] "C" Vector__XXX
 SG_ Temp14 : 40|8@0+ (1,0) [0|120] "C" Vector__XXX
 SG_ Temp15 : 48|8@0+ (1,0) [0|120] "C" Vector__XXX
 SG_ Temp16 : 56|8@0+ (1,0) [0|120] "C" Vector__XXX

BO_ 261 Temp3: 8 Vector__XXX
 SG_ Temp17 : 0|8@0+ (1,0) [0|120] "C" Vector__XXX
 SG_ Temp18 : 8|8@0+ (1,0) [0|120] "C" Vector__XXX
 SG_ Temp19 : 16|8@0+ (1,0) [0|120] "C" Vector__XXX
 SG_ Temp20 : 24|8@0+ (1,0) [0|120] "C" Vector__XXX
 SG_ Temp21 : 32|8@0+ (1,0) [0|120] "C" Vector__XXX
 SG_ Temp22 : 40|8@0+ (1,0) [0|120] "C" Vector__XXX
 SG_ Temp23 : 48|8@0+ (1,0) [0|120] "C" Vector__XXX
 SG_ Temp24 : 56|8@0+ (1,0) [0|120] "C" Vector__XXX

BO_ 262 Temp4: 8 Vector__XXX
 SG_ Temp25 : 0|8@0+ (1,0) [0|120] "C" Vector__XXX
 SG_ Temp26 : 8|8@0+ (1,0) [0|120] "C" Vector__XXX
 SG_ Temp27 : 16|8@0+ (1,0) [0|120] "C" Vector__XXX
 SG_ Temp28 : 24|8@0+ (1,0) [0|120] "C" Vector__XXX
 SG_ Temp29 : 32|8@0+ (1,0) [0|120] "C" Vector__XXX
 SG_ Temp30 : 40|8@0+ (1,0) [0|120] "C" Vector__XXX
 SG_ Temp31 : 48|8@0+ (1,0) [0|120] "C" Vector__XXX
 SG_ Temp32 : 56|8@0+ (1,0) [0|120] "C" Vector__XXX

BO_ 263 Temp5: 8 Vector__XXX
 SG_ Temp33 : 0|8@0+ (1,0) [0|120] "C" Vector__XXX
 SG_ Temp34 : 8|8@0+ (1,0) [0|120] "C" Vector__XXX
 SG_ Temp35 : 16|8@0+ (1,0) [0|120] "C" Vector__XXX
 SG_ Temp36 : 24|8@0+ (1,0) [0|120] "C" Vector__XXX
 SG_ Temp37 : 32|8@0+ (1,0) [0|120] "C" Vector__XXX
 SG_ Temp38 : 40|8@0+ (1,0) [0|120] "C" Vector__XXX
 SG_ Temp39 : 48|8@0+ (1,0) [0|120] "C" Vector__XXX
 SG_ Temp40 : 56|8@0+ (1,0) [0|120] "C" Vector__XXX

BO_ 264 Temp6: 8 Vector__XXX
 SG_ Temp41 : 0|8@0+ (1,0) [0|120] "C" Vector__XXX
 SG_ Temp42 : 8|8@0+ (1,0) [0|120] "C" Vector__XXX
 SG_ Temp43 : 16|8@0+ (1,0) [0|120] "C" Vector__XXX
 SG_ Temp44 : 24|8@0+ (1,0) [0|120] "C" Vector__XXX
 SG_ Temp45 : 32|8@0+ (1,0) [0|120] "C" Vector__XXX
 SG_ Temp46 : 40|8@0+ (1,0) [0|120] "C" Vector__XXX
 SG_ Temp47 : 48|8@0+ (1,0) [0|120] "C" Vector__XXX
 SG_ Temp48 : 56|8@0+ (1,0) [0|120] "C" Vector__XXX

BO_ 265 Voltage1: 8 Vector__XXX
 SG_ Cell1 : 0|8@0+ (0.01,100) [2.5|4.3] "V" Vector__XXX
 SG_ Cell2 : 8|8@0+ (0.01,100) [2.5|4.3] "V" Vector__XXX
 SG_ Cell3 : 16|8@0+ (0.01,100) [2.5|4.3] "V" Vector__XXX
 SG_ Cell4 : 24|8@0+ (0.01,100) [2.5|4.3] "V" Vector__XXX
 SG_ Cell5 : 32|8@0+ (0.01,100) [2.5|4.3] "V" Vector__XXX
 SG_ Cell6 : 40|8@0+ (0.01,100) [2.5|4.3] "V" Vector__XXX
 SG_ Cell7 : 48|8@0+ (0.01,100) [2.5|4.3] "V" Vector__XXX
 SG_ Cell8 : 56|8@0+ (0.01,100) [2.5|4.3] "V" Vector__XXX

BO_ 266 Voltage2: 8 Vector__XXX
 SG_ Cell9 : 0|8@0+ (0.01,100) [2.5|4.3] "V" Vector__XXX
 SG_ Cell10 : 8|8@0+ (0.01,100) [2.5|4.3] "V" Vector__XXX
 SG_ Cell11 : 16|8@0+ (0.01,100) [2.5|4.3] "V" Vector__XXX
 SG_ Cell12 : 24|8@0+ (0.01,100) [2.5|4.3] "V" Vector__XXX
 SG_ Cell13 : 32|8@0+ (0.01,100) [2.5|4.3] "V" Vector__XXX
 SG_ Cell14 : 40|8@0+ (0.01,100) [2.5|4.3] "V" Vector__XXX
 SG_ Cell15 : 48|8@0+ (0.01,100) [2.5|4.3] "V" Vector__XXX
 SG_ Cell16 : 56|8@0+ (0.01,100) [2.5|4.3] "V" Vector__XXX

BO_ 267 Voltage3: 8 Vector__XXX
 SG_ Cell17 : 0|8@0+ (0.01,100) [2.5|4.3] "V" Vector__XXX
 SG_ Cell18 : 8|8@0+ (0.01,100) [2.5|4.3] "V" Vector__XXX
 SG_ Cell19 : 16|8@0+ (0.01,100) [2.5|4.3] "V" Vector__XXX
 SG_ Cell20 : 24|8@0+ (0.01,100) [2.5|4.3] "V" Vector__XXX
 SG_ Cell21 : 32|8@0+ (0.01,100) [2.5|4.3] "V" Vector__XXX
 SG_ Cell22 : 40|8@0+ (0.01,100) [2.5|4.3] "V" Vector__XXX
 SG_ Cell23 : 48|8@0+ (0.01,100) [2.5|4.3] "V" Vector__XXX
 SG_ Cell24 : 56|8@0+ (0.01,100) [2.5|4.3] "V" Vector__XXX

BO_ 268 Voltage4: 8 Vector__XXX
 SG_ Cell25 : 0|8@0+ (0.01,100) [2.5|4.3] "V" Vector__XXX
 SG_ Cell26 : 8|8@0+ (0.01,100) [2.5|4.3] "V" Vector__XXX
 SG_ Cell27 : 16|8@0+ (0.01,100) [2.5|4.3] "V" Vector__XXX
 SG_ Cell28 : 24|8@0+ (0.01,100) [2.5|4.3] "V" Vector__XXX
 SG_ Cell29 : 32|8@0+ (0.01,100) [2.5|4.3] "V" Vector__XXX
 SG_ Cell30 : 40|8@0+ (0.01,100) [2.5|4.3] "V" Vector__XXX
 SG_ Cell31 : 48|8@0+ (0.01,100) [2.5|4.3] "V" Vector__XXX
 SG_ Cell32 : 56|8@0+ (0.01,100) [2.5|4.3] "V" Vector__XXX

BO_ 269 Voltage5: 8 Vector__XXX
 SG_ Cell33 : 0|8@0+ (0.01,100) [2.5|4.3] "V" Vector__XXX
 SG_ Cell34 : 8|8@0+ (0.01,100) [2.5|4.3] "V" Vector__XXX
 SG_ Cell35 : 16|8@0+ (0.01,100) [2.5|4.3] "V" Vector__XXX
 SG_ Cell36 : 24|8@0+ (0.01,100) [2.5|4.3] "V" Vector__XXX
 SG_ Cell37 : 32|8@0+ (0.01,100) [2.5|4.3] "V" Vector__XXX
 SG_ Cell38 : 40|8@0+ (0.01,100) [2.5|4.3] "V" Vector__XXX
 SG_ Cell39 : 48|8@0+ (0.01,100) [2.5|4.3] "V" Vector__XXX
 SG_ Cell40 : 56|8@0+ (0.01,100) [2.5|4.3] "V" Vector__XXX

BO_ 270 Voltage6: 8 Vector__XXX
 SG_ Cell41 : 0|8@0+ (0.01,100) [2.5|4.3] "V" Vector__XXX
 SG_ Cell42 : 8|8@0+ (0.01,100) [2.5|4.3] "V" Vector__XXX
 SG_ Cell43 : 16|8@0+ (0.01,100) [2.5|4.3] "V" Vector__XXX
 SG_ Cell44 : 24|8@0+ (0.01,100) [2.5|4.3] "V" Vector__XXX
 SG_ Cell45 : 32|8@0+ (0.01,100) [2.5|4.3] "V" Vector__XXX
 SG_ Cell46 : 40|8@0+ (0.01,100) [2.5|4.3] "V" Vector__XXX
 SG_ Cell47 : 48|8@0+ (0.01,100) [2.5|4.3] "V" Vector__XXX
 SG_ Cell48 : 56|8@0+ (0.01,100) [2.5|4.3] "V" Vector__XXX

BO_ 271 Voltage7: 8 Vector__XXX
 SG_ Cell49 : 0|8@0+ (0.01,100) [2.5|4.3] "V" Vector__XXX
 SG_ Cell50 : 8|8@0+ (0.01,100) [2.5|4.3] "V" Vector__XXX
 SG_ Cell51 : 16|8@0+ (0.01,100) [2.5|4.3] "V" Vector__XXX
 SG_ Cell52 : 24|8@0+ (0.01,100) [2.5|4.3] "V" Vector__XXX
 SG_ Cell53 : 32|8@0+ (0.01,100) [2.5|4.3] "V" Vector__XXX
 SG_ Cell54 : 40|8@0+ (0.01,100) [2.5|4.3] "V" Vector__XXX
 SG_ Cell55 : 48|8@0+ (0.01,100) [2.5|4.3] "V" Vector__XXX
 SG_ Cell56 : 56|8@0+ (0.01,100) [2.5|4.3] "V" Vector__XXX

BO_ 272 Voltage8: 8 Vector__XXX
 SG_ Cell57 : 0|8@0+ (0.01,100) [2.5|4.3] "V" Vector__XXX
 SG_ Cell58 : 8|8@0+ (0.01,100) [2.5|4.3] "V" Vector__XXX
 SG_ Cell59 : 16|8@0+ (0.01,100) [2.5|4.3] "V" Vector__XXX
 SG_ Cell60 : 24|8@0+ (0.01,100) [2.5|4.3] "V" Vector__XXX
 SG_ Cell61 : 32|8@0+ (0.01,100) [2.5|4.3] "V" Vector__XXX
 SG_ Cell62 : 40|8@0+ (0.01,100) [2.5|4.3] "V" Vector__XXX
 SG_ Cell63 : 48|8@0+ (0.01,100) [2.5|4.3] "V" Vector__XXX
 SG_ Cell64 : 56|8@0+ (0.01,100) [2.5|4.3] "V" Vector__XXX

BO_ 273 Voltage9: 8 Vector__XXX
 SG_ Cell65 : 0|8@0+ (0.01,100) [2.5|4.3] "V" Vector__XXX
 SG_ Cell66 : 8|8@0+ (0.01,100) [2.5|4.3] "V" Vector__XXX
 SG_ Cell67 : 16|8@0+ (0.01,100) [2.5|4.3] "V" Vector__XXX
 SG_ Cell68 : 24|8@0+ (0.01,100) [2.5|4] "V" Vector__XXX
 SG_ Cell69 : 32|8@0+ (0.01,100) [2.5|4.3] "V" Vector__XXX
 SG_ Cell70 : 40|8@0+ (0.01,100) [2.5|4.3] "V" Vector__XXX
 SG_ Cell71 : 48|8@0+ (0.01,100) [2.5|4.3] "V" Vector__XXX
 SG_ Cell72 : 56|8@0+ (0.01,100) [2.5|4.3] "V" Vector__XXX

BO_ 274 Voltage10: 8 Vector__XXX
 SG_ Cell73 : 0|8@0+ (0.01,100) [2.5|4.3] "V" Vector__XXX
 SG_ Cell74 : 8|8@0+ (0.01,100) [2.5|4.3] "V" Vector__XXX
 SG_ Cell75 : 16|8@0+ (0.01,100) [2.5|4.3] "V" Vector__XXX
 SG_ Cell76 : 24|8@0+ (0.01,100) [2.5|4.3] "V" Vector__XXX
 SG_ Cell77 : 32|8@0+ (0.01,100) [2.5|4.3] "V" Vector__XXX
 SG_ Cell78 : 40|8@0+ (0.01,100) [2.5|4.3] "V" Vector__XXX
 SG_ Cell79 : 48|8@0+ (0.01,100) [2.5|4.3] "V" Vector__XXX
 SG_ Cell80 : 56|8@0+ (0.01,100) [2.5|4.3] "V" Vector__XXX

BO_ 275 Voltage11: 8 Vector__XXX
 SG_ Cell81 : 0|8@0+ (0.01,100) [2.5|4.3] "V" Vector__XXX
 SG_ Cell82 : 8|8@0+ (0.01,100) [2.5|4.3] "V" Vector__XXX
 SG_ Cell83 : 16|8@0+ (0.01,100) [2.5|4.3] "V" Vector__XXX
 SG_ Cell84 : 24|8@0+ (0.01,100) [2.5|4.3] "V" Vector__XXX
 SG_ Cell85 : 32|8@0+ (0.01,100) [2.5|4.3] "V" Vector__XXX
 SG_ Cell86 : 40|8@0+ (0.01,100) [2.5|4.3] "V" Vector__XXX
 SG_ Cell87 : 48|8@0+ (0.01,100) [2.5|4.3] "V" Vector__XXX
 SG_ Cell88 : 56|8@0+ (0.01,100) [2.5|4.3] "V" Vector__XXX

BO_ 276 Voltage12: 8 Vector__XXX
 SG_ Cell89 : 0|8@0+ (0.01,100) [2.5|4.3] "V" Vector__XXX
 SG_ Cell90 : 8|8@0+ (0.01,100) [2.5|4.3] "V" Vector__XXX
 SG_ Cell91 : 16|8@0+ (0.01,100) [2.5|4.3] "V" Vector__XXX
 SG_ Cell92 : 24|8@0+ (0.01,100) [2.5|4.3] "V" Vector__XXX
 SG_ Cell93 : 32|8@0+ (0.01,100) [2.5|4.3] "V" Vector__XXX
 SG_ Cell94 : 40|8@0+ (0.01,100) [2.5|4.3] "V" Vector__XXX
 SG_ Cell95 : 48|8@0+ (0.01,100) [2.5|4.3] "V" Vector__XXX
 SG_ Cell96 : 56|8@0+ (0.01,100) [2.5|4.3] "V" Vector__XXX

BO_ 1712 OrionMSG1: 8 Vector__XXX
 SG_ Pack_Inst_voltage : 15|16@0+ (0.1,0) [0|6553.5] "" Vector__XXX
 SG_ Pack_SOC : 39|8@0+ (0.5,0) [0|127.5] "" Vector__XXX

BO_ 1713 OrionMSG2: 8 Vector__XXX
 SG_ Pack_High_Temp : 39|8@0- (1,0) [-128|127] "" Vector__XXX
 SG_ Pack_Low_Temp : 47|8@0- (1,0) [-128|127] "" Vector__XXX

BO_ 1714 OrionMSG3: 8 Vector__XXX
 SG_ Low_Cell_Voltage : -1|16@0+ (0.0001,0) [0|6.5535] "" Vector__XXX
 SG_ High_Cell_Voltage : 15|16@0+ (0.0001,0) [0|6.5535] "" Vector__XXX

BO_ 77823936 M100_VCU_States1: 8 VCU
 SG_ Run_Mode_State : 8|2@1+ (1,0) [0|3] "" VCU
 SG_ Drive_Mode_State : 10|4@1+ (1,0) [0|15] "" VCU
 SG_ Run_Time : 14|10@1+ (1,0) [0|1023] "s" VCU
 SG_ Stop_Command_State : 16|1@1+ (1,0) [0|1] "" VCU
 SG_ Start_Command_State : 17|1@1+ (1,0) [0|1] "" VCU
 SG_ OPState : 18|6@1+ (1,0) [0|63] "" VCU
 SG_ MC2DischargeCmd : 24|1@1+ (1,0) [0|1] "" VCU
 SG_ MC1DischargeCmd : 25|1@1+ (1,0) [0|1] "" VCU
 SG_ MCPower : 26|1@1+ (1,0) [0|1] "" VCU
 SG_ MC4Enable : 27|1@1+ (1,0) [0|1] "" VCU
 SG_ MC3Enable : 28|1@1+ (1,0) [0|1] "" VCU
 SG_ MC2Enable : 29|1@1+ (1,0) [0|1] "" VCU
 SG_ MC1Enable : 30|1@1+ (1,0) [0|1] "" VCU
 SG_ Start_Safe : 31|1@1+ (1,0) [0|1] "" VCU
 SG_ MC3ContEnable : 32|1@1+ (1,0) [0|1] "" VCU
 SG_ MC2ContEnable : 33|1@1+ (1,0) [0|1] "" VCU
 SG_ MC1ContEnable : 34|1@1+ (1,0) [0|1] "" VCU
 SG_ PumpCont_XCheck : 35|1@1+ (1,0) [0|1] "" VCU
 SG_ HVIL_Charge : 36|1@1+ (1,0) [0|1] "" VCU
 SG_ HVIL_Main : 37|1@1+ (1,0) [0|1] "" VCU
 SG_ MC4DischargeCmd : 38|1@1+ (1,0) [0|1] "" VCU
 SG_ MC3DischargeCmd : 39|1@1+ (1,0) [0|1] "" VCU
 SG_ MC1_PosFB : 40|1@1+ (1,0) [0|1] "" VCU
 SG_ MC1_NegFB : 41|1@1+ (1,0) [0|1] "" VCU
 SG_ MC1_HVDetect : 42|1@1+ (1,0) [0|1] "" VCU
 SG_ MC4_DCVoltageSafeState : 43|1@1+ (1,0) [0|1] "" VCU
 SG_ MC3_DCVoltageSafeState : 44|1@1+ (1,0) [0|1] "" VCU
 SG_ MC2_DCVoltageSafeState : 45|1@1+ (1,0) [0|1] "" VCU
 SG_ MC1_DCVoltageSafeState : 46|1@1+ (1,0) [0|1] "" VCU
 SG_ MC4ContEnable : 47|1@1+ (1,0) [0|1] "" VCU
 SG_ MC3_PosFB : 48|1@1+ (1,0) [0|1] "" VCU
 SG_ MC3_NegFB : 49|1@1+ (1,0) [0|1] "" VCU
 SG_ MC3_HVDetect : 50|1@1+ (1,0) [0|1] "" VCU
 SG_ MC2_PreChgFB : 51|1@1+ (1,0) [0|1] "" VCU
 SG_ MC2_PosFB : 52|1@1+ (1,0) [0|1] "" VCU
 SG_ MC2_NegFB : 53|1@1+ (1,0) [0|1] "" VCU
 SG_ MC2_HVDetect : 54|1@1+ (1,0) [0|1] "" VCU
 SG_ MC1_PreChgFB : 55|1@1+ (1,0) [0|1] "" VCU
 SG_ Performance_Level : 56|3@1+ (1,0) [0|7] "" VCU
 SG_ MC4_PreChgFB : 59|1@1+ (1,0) [0|1] "" VCU
 SG_ MC4_PosFB : 60|1@1+ (1,0) [0|1] "" VCU
 SG_ MC4_NegFB : 61|1@1+ (1,0) [0|1] "" VCU
 SG_ MC4_HVDetect : 62|1@1+ (1,0) [0|1] "" VCU
 SG_ MC3_PreChgFB : 63|1@1+ (1,0) [0|1] "" VCU

BO_ 77823938 M102_VCU_States2: 8 VCU
 SG_ VCU_12V_Input : 0|8@1+ (0.1,0) [0|25.5] "V" VCU
 SG_ MC1_PreChg_Cmd : 8|1@1+ (1,0) [0|1] "" VCU
 SG_ MC1_Pos_Cmd : 9|1@1+ (1,0) [0|1] "" VCU
 SG_ VCU_5V_Output : 10|6@1+ (0.1,0) [0|6.3] "V" VCU
 SG_ MC4_Pos_Cmd : 16|1@1+ (1,0) [0|1] "" VCU
 SG_ MC3_PreChgComplete : 17|1@1+ (1,0) [0|1] "" VCU
 SG_ MC3_PreChg_Cmd : 18|1@1+ (1,0) [0|1] "" VCU
 SG_ MC3_Pos_Cmd : 19|1@1+ (1,0) [0|1] "" VCU
 SG_ MC2_PreChgComplete : 20|1@1+ (1,0) [0|1] "" VCU
 SG_ MC2_PreChg_Cmd : 21|1@1+ (1,0) [0|1] "" VCU
 SG_ MC2_Pos_Cmd : 22|1@1+ (1,0) [0|1] "" VCU
 SG_ MC1_PreChgComplete : 23|1@1+ (1,0) [0|1] "" VCU
 SG_ SpeedMode_Allowed : 24|1@1+ (1,0) [0|1] "" VCU
 SG_ InvControl_Mode : 25|1@1+ (1,0) [0|1] "" VCU
 SG_ Launch_Mode : 26|1@1+ (1,0) [0|1] "" VCU
 SG_ Burnout_Mode : 27|1@1+ (1,0) [0|1] "" VCU
 SG_ Idle_Mode : 28|1@1+ (1,0) [0|1] "" VCU
 SG_ Creep_Mode : 29|1@1+ (1,0) [0|1] "" VCU
 SG_ MC4_PreChgComplete : 30|1@1+ (1,0) [0|1] "" VCU
 SG_ MC4_PreChg_Cmd : 31|1@1+ (1,0) [0|1] "" VCU
 SG_ LineLock_Cntrl : 32|1@1+ (1,0) [0|1] "" VCU
 SG_ TransBrake_Cntrl : 33|1@1+ (1,0) [0|1] "" VCU
 SG_ Cool_Pump_Wake : 34|1@1+ (1,0) [0|1] "" VCU
 SG_ Cool_Pump2_Cntrl : 35|1@1+ (1,0) [0|1] "" VCU
 SG_ Cool_Pump1_Cntrl : 36|1@1+ (1,0) [0|1] "" VCU
 SG_ OilPump1_On : 37|1@1+ (1,0) [0|1] "" VCU
 SG_ Cool_Fan2_On : 38|1@1+ (1,0) [0|1] "" VCU
 SG_ Cool_Fan1_On : 39|1@1+ (1,0) [0|1] "" VCU
 SG_ Cool_PumpSpdTarget : 40|8@1+ (25,0) [0|6375] "rpm" VCU
 SG_ Brake_LampsCntrl : 48|1@1+ (1,0) [0|1] "" VCU
 SG_ TransBrake_Switch : 49|1@1+ (1,0) [0|1] "" VCU
 SG_ LineLock_Switch : 50|1@1+ (1,0) [0|1] "" VCU
 SG_ Inertia_Switch : 51|1@1+ (1,0) [0|1] "" VCU
 SG_ IMDState : 52|1@1+ (1,0) [0|1] "" VCU
 SG_ ShiftSol_Cntrl : 53|1@1+ (1,0) [0|1] "" VCU
 SG_ Shift_Sol2 : 54|1@1+ (1,0) [0|1] "" VCU
 SG_ Shift_Sol1 : 55|1@1+ (1,0) [0|1] "" VCU
 SG_ Contactors_Enabled : 56|1@1+ (1,0) [0|1] "" VCU
 SG_ ChargeContactorCntrl : 57|1@1+ (1,0) [0|1] "" VCU
 SG_ Acc_PowerCntrl : 58|1@1+ (1,0) [0|1] "" VCU
 SG_ Acc_LightCntrl : 59|1@1+ (1,0) [0|1] "" VCU
 SG_ ReverseLamps_Cntrl : 60|1@1+ (1,0) [0|1] "" VCU
 SG_ ParkLamps_Cntrl : 61|1@1+ (1,0) [0|1] "" VCU
 SG_ HVSafetyLight_Cntrl : 62|1@1+ (1,0) [0|1] "" VCU
 SG_ Head_LampsCntrl : 63|1@1+ (1,0) [0|1] "" VCU

BO_ 77823940 M104_VCU_States3: 8 VCU
 SG_ LimMult_MC1Temp_Active : 0|1@1+ (1,0) [0|1] "" VCU
 SG_ LimMult_MC1Curr_Active : 1|1@1+ (1,0) [0|1] "" VCU
 SG_ LimMult_Launch_Time_Active : 2|1@1+ (1,0) [0|1] "" VCU
 SG_ LimMult_DriveShaft_Spd_Active : 3|1@1+ (1,0) [0|1] "" VCU
 SG_ LimMult_CellVolt_Min_Active : 4|1@1+ (1,0) [0|1] "" VCU
 SG_ LimMult_CellVolt_Max_Active : 5|1@1+ (1,0) [0|1] "" VCU
 SG_ LimMult_Batt_SOC_Active : 6|1@1+ (1,0) [0|1] "" VCU
 SG_ LimMult_Batt_DCL_Active : 7|1@1+ (1,0) [0|1] "" VCU
 SG_ LimMult_Motor1_Temp_Active : 8|1@1+ (1,0) [0|1] "" VCU
 SG_ LimMult_Motor1_SpdLo_Active : 9|1@1+ (1,0) [0|1] "" VCU
 SG_ LimMult_MC4Temp_Active : 10|1@1+ (1,0) [0|1] "" VCU
 SG_ LimMult_MC4Curr_Active : 11|1@1+ (1,0) [0|1] "" VCU
 SG_ LimMult_MC3Temp_Active : 12|1@1+ (1,0) [0|1] "" VCU
 SG_ LimMult_MC3Curr_Active : 13|1@1+ (1,0) [0|1] "" VCU
 SG_ LimMult_MC2Temp_Active : 14|1@1+ (1,0) [0|1] "" VCU
 SG_ LimMult_MC2Curr_Active : 15|1@1+ (1,0) [0|1] "" VCU
 SG_ LimMult_Pack_Current_Active : 16|1@1+ (1,0) [0|1] "" VCU
 SG_ LimMult_Over_rev_Active : 17|1@1+ (1,0) [0|1] "" VCU
 SG_ LimMult_Motor4_Temp_Active : 18|1@1+ (1,0) [0|1] "" VCU
 SG_ LimMult_Motor4_SpdLo_Active : 19|1@1+ (1,0) [0|1] "" VCU
 SG_ LimMult_Motor3_Temp_Active : 20|1@1+ (1,0) [0|1] "" VCU
 SG_ LimMult_Motor3_SpdLo_Active : 21|1@1+ (1,0) [0|1] "" VCU
 SG_ LimMult_Motor2_Temp_Active : 22|1@1+ (1,0) [0|1] "" VCU
 SG_ LimMult_Motor2_SpdLo_Active : 23|1@1+ (1,0) [0|1] "" VCU
 SG_ LimMult_Shift5_Tq_Active : 24|1@1+ (1,0) [0|1] "" VCU
 SG_ LimMult_Shift4_Tq_Active : 25|1@1+ (1,0) [0|1] "" VCU
 SG_ LimMult_Shift3_Tq_Active : 26|1@1+ (1,0) [0|1] "" VCU
 SG_ LimMult_Shift2_Tq_Active : 27|1@1+ (1,0) [0|1] "" VCU
 SG_ LimMult_Shift1_Tq_Active : 28|1@1+ (1,0) [0|1] "" VCU
 SG_ LimMult_Pack_Voltage_Active : 29|1@1+ (1,0) [0|1] "" VCU
 SG_ LimMult_Pack_TempLo_Active : 30|1@1+ (1,0) [0|1] "" VCU
 SG_ LimMult_Pack_TempHi_Active : 31|1@1+ (1,0) [0|1] "" VCU
 SG_ LaunchTimer_Running : 33|1@1+ (1,0) [0|1] "" VCU
 SG_ LimMult_MC4CurrRamp_Active : 34|1@1+ (1,0) [0|1] "" VCU
 SG_ LimMult_MC3CurrRamp_Active : 35|1@1+ (1,0) [0|1] "" VCU
 SG_ LimMult_MC2CurrRamp_Active : 36|1@1+ (1,0) [0|1] "" VCU
 SG_ LimMult_MC1CurrRamp_Active : 37|1@1+ (1,0) [0|1] "" VCU
 SG_ LimMult_VehSpd_Lo_Active : 38|1@1+ (1,0) [0|1] "" VCU
 SG_ LimMult_VehSpd_Hi_Active : 39|1@1+ (1,0) [0|1] "" VCU
 SG_ LaunchRamp_Time : 40|8@1+ (0.1,0) [0|25.5] "s" VCU
 SG_ Run_Time_Counter : 56|16@1+ (1,0) [0|65535] "s" VCU

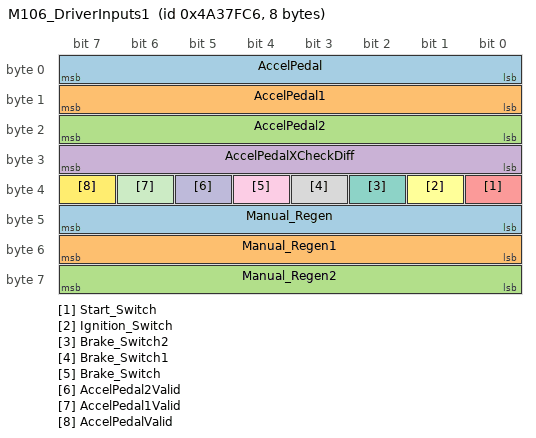
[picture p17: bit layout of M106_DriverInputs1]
BO_ 77823942 M106_DriverInputs1: 8 VCU
 SG_ AccelPedal : 0|8@1+ (0.392157,0) [0|99.9999993] "" VCU
 SG_ AccelPedal1 : 8|8@1+ (0.392157,0) [0|99.9999993] "" VCU
 SG_ AccelPedal2 : 16|8@1+ (0.392157,0) [0|99.9999993] "" VCU
 SG_ AccelPedalXCheckDiff : 24|8@1+ (0.392157,0) [0|99.9999993] "" VCU
 SG_ Start_Switch : 32|1@1+ (1,0) [0|1] "" VCU
 SG_ Ignition_Switch : 33|1@1+ (1,0) [0|1] "" VCU
 SG_ Brake_Switch2 : 34|1@1+ (1,0) [0|1] "" VCU
 SG_ Brake_Switch1 : 35|1@1+ (1,0) [0|1] "" VCU
 SG_ Brake_Switch : 36|1@1+ (1,0) [0|1] "" VCU
 SG_ AccelPedal2Valid : 37|1@1+ (1,0) [0|1] "" VCU
 SG_ AccelPedal1Valid : 38|1@1+ (1,0) [0|1] "" VCU
 SG_ AccelPedalValid : 39|1@1+ (1,0) [0|1] "" VCU
 SG_ Manual_Regen : 40|8@1+ (0.392157,0) [0|99.9999993] "" VCU
 SG_ Manual_Regen1 : 48|8@1+ (0.392157,0) [0|99.9999993] "" VCU
 SG_ Manual_Regen2 : 56|8@1+ (0.392157,0) [0|99.9999993] "" VCU

BO_ 77823944 M108_DriverInputs2: 8 VCU
 SG_ ManRegen_XCheckDiff : 0|8@1+ (0.392157,0) [0|99.9999993] "" VCU
 SG_ ParkLamp_Switch : 8|1@1+ (1,0) [0|1] "" VCU
 SG_ Head_LampSwitch : 9|1@1+ (1,0) [0|1] "" VCU
 SG_ Reverse_Switch : 10|1@1+ (1,0) [0|1] "" VCU
 SG_ Drive_Switch : 11|1@1+ (1,0) [0|1] "" VCU
 SG_ Neutral_Switch : 12|1@1+ (1,0) [0|1] "" VCU
 SG_ Park_Switch : 13|1@1+ (1,0) [0|1] "" VCU
 SG_ Manual_Regen2Valid : 14|1@1+ (1,0) [0|1] "" VCU
 SG_ Manual_Regen1Valid : 15|1@1+ (1,0) [0|1] "" VCU
 SG_ Logging_Switch : 16|1@1+ (1,0) [0|1] "" VCU
 SG_ Wake_Switch : 17|1@1+ (1,0) [0|1] "" VCU
 SG_ Acc_LightSwitch : 18|1@1+ (1,0) [0|1] "" VCU
 SG_ ACSwitch : 19|1@1+ (1,0) [0|1] "" VCU
 SG_ HeaterSwitch : 20|1@1+ (1,0) [0|1] "" VCU
 SG_ Cooling_PumpOrdSwitch : 21|1@1+ (1,0) [0|1] "" VCU
 SG_ Cooling_FanOrdSwitch : 22|1@1+ (1,0) [0|1] "" VCU
 SG_ Enable_Switch : 23|1@1+ (1,0) [0|1] "" VCU
 SG_ CCSetCst : 28|1@1+ (1,0) [0|1] "" VCU
 SG_ CCRsmAcc : 29|1@1+ (1,0) [0|1] "" VCU
 SG_ CCOn : 30|1@1+ (1,0) [0|1] "" VCU
 SG_ CCCancel : 31|1@1+ (1,0) [0|1] "" VCU

BO_ 77823954 M112_VehicleInputs1: 8 VCU
 SG_ Brake_Pressure : 8|16@1+ (0.1,0) [0|6553.5] "psi" VCU
 SG_ Transmission_Pressure : 24|16@1+ (0.1,0) [0|6553.5] "psi" VCU
 SG_ WheelBar_Press1 : 40|16@1+ (0.1,0) [0|6553.5] "psi" VCU
 SG_ WheelBar_Press2 : 56|16@1+ (0.1,0) [0|6553.5] "psi" VCU

BO_ 77823956 M114_VehicleInputs2: 8 VCU
 SG_ Transmission_Temp : 0|8@1+ (1,-50) [-50|205] "C" VCU
 SG_ Coolant_Temp1 : 8|8@1+ (1,0) [-128|127] "C" VCU
 SG_ Coolant_Temp2 : 16|8@1- (1,0) [-128|127] "C" VCU
 SG_ AmbientAirTemp : 24|8@1- (1,0) [-128|127] "C" VCU
 SG_ HeaterInletTemp : 32|8@1- (1,0) [-128|127] "C" VCU
 SG_ HeaterOutletTemp : 40|8@1- (1,0) [-128|127] "C" VCU
 SG_ ACPressure : 56|16@1+ (0.1,0) [0|6553.5] "psi" VCU

BO_ 77823958 M116_VehicleInputs3: 7 VCU
 SG_ BrakeVacPressure : 0|8@1+ (0.14504,-14.696) [-14.696|22.2892] "psi" VCU
 SG_ Vehicle_Speed : 8|8@1+ (1,0) [0|255] "mph" VCU
 SG_ DriveShaft_Speed : 24|16@1+ (1,0) [0|65535] "rpm" VCU
 SG_ DriveWheel_Speed : 32|8@1+ (1,0) [0|255] "mph" VCU
 SG_ Ground_WheelSpeed : 40|8@1+ (1,0) [0|255] "mph" VCU
 SG_ TC_Slip_Measured : 48|8@1+ (1,0) [0|255] "mph" VCU

BO_ 77823960 M118_VehicleInputs4: 4 VCU
 SG_ Vehicle_Odometer : 24|32@1+ (0.01,0) [0|42949672.95] "mi" VCU

BO_ 77823968 M120_MotorTorqueData1: 8 VCU
 SG_ Motor1_Torque_Request : 12|12@1- (0.5,0) [-1024|1023.5] "N.m" VCU
 SG_ Motor1_TqLimHi : 16|12@1+ (0.5,0) [0|2047.5] "N.m" VCU
 SG_ Motor1_TqLimLo : 36|12@1- (0.5,0) [-1024|1023.5] "N.m" VCU
 SG_ Motor1_TqTable : 40|12@1+ (0.5,0) [0|2047.5] "N.m" VCU
 SG_ Motor1_TqLimMultHi : 48|8@1+ (0.005,0) [0|1.275] "frac" VCU
 SG_ Motor1_TqLimMultLo : 56|8@1+ (0.005,0) [0|1.275] "frac" VCU

BO_ 77823970 M122_MotorTorqueData2: 8 VCU
 SG_ Motor1_CreepTorque : 12|12@1+ (0.1,0) [0|409.5] "N.m" VCU
 SG_ Motor1_ReverseTorque : 16|12@1+ (0.1,0) [0|409.5] "N.m" VCU
 SG_ Motor1_TorqueTrimTable : 36|12@1- (0.001,0) [-2.048|2.047] "frac" VCU
 SG_ MotorTqSpd_FeedForward : 40|12@1+ (0.5,0) [0|2047.5] "N.m" VCU
 SG_ PedalTqMult_Tbl1 : 48|8@1- (1,0) [-128|127] "" VCU
 SG_ PedalTqMult_Tbl2 : 56|8@1- (1,0) [-128|127] "" VCU

BO_ 77823972 M124_MotorTorqueData3: 8 VCU
 SG_ Motor2_TorqueRequest : 12|12@1- (0.5,0) [-1024|1023.5] "N.m" VCU
 SG_ Motor2_TqLimHi : 16|12@1+ (0.5,0) [0|2047.5] "N.m" VCU
 SG_ Motor2_TqLimLo : 36|12@1- (0.5,0) [-1024|1023.5] "N.m" VCU
 SG_ Motor2_TqTable : 40|12@1+ (0.5,0) [0|2047.5] "N.m" VCU
 SG_ Motor2_TqLimMultHi : 48|8@1+ (0.005,0) [0|1.275] "frac" VCU
 SG_ Motor2_TqLimMultLo : 56|8@1+ (0.005,0) [0|1.275] "frac" VCU

BO_ 77823974 M126_MotorTorqueData4: 8 VCU
 SG_ Motor2_CreepTorque : 12|12@1+ (0.1,0) [0|409.5] "N.m" VCU
 SG_ Motor2_ReverseTorque : 16|12@1+ (0.1,0) [0|409.5] "N.m" VCU
 SG_ Motor2_TorqueTrimTable : 36|12@1- (0.001,0) [-2.048|2.047] "frac" VCU
 SG_ RegenBrake_Torque : 40|12@1+ (0.5,0) [0|2047.5] "N.m" VCU
 SG_ PedalTqMult_Tbl3 : 48|8@1- (1,0) [-128|127] "" VCU
 SG_ PedalTqMult_Tbl4 : 56|8@1- (1,0) [-128|127] "" VCU

BO_ 77823976 M128_MotorTorqueData5: 8 VCU
 SG_ Motor3_TorqueRequest : 12|12@1- (0.5,0) [-1024|1023.5] "N.m" VCU
 SG_ Motor3_TqLimHi : 16|12@1+ (0.5,0) [0|2047.5] "N.m" VCU
 SG_ Motor3_TqLimLo : 36|12@1- (0.5,0) [-1024|1023.5] "N.m" VCU
 SG_ Motor3_TqTable : 40|12@1+ (0.5,0) [0|2047.5] "N.m" VCU
 SG_ Motor3_TqLimMultHi : 48|8@1+ (0.005,0) [0|1.275] "frac" VCU
 SG_ Motor3_TqLimMultLo : 56|8@1+ (0.005,0) [0|1.275] "frac" VCU

BO_ 77823978 M130_MotorTorqueData6: 8 VCU
 SG_ Motor3_CreepTorque : 12|12@1+ (0.1,0) [0|409.5] "N.m" VCU
 SG_ Motor3_ReverseTorque : 16|12@1+ (0.1,0) [0|409.5] "N.m" VCU
 SG_ Motor3_TorqueTrimTable : 36|12@1- (0.001,0) [-2.048|2.047] "frac" VCU
 SG_ Motor4_TorqueRequest : 40|12@1- (0.5,0) [-1024|1023.5] "N.m" VCU

BO_ 77823980 M132_MotorTorqueData7: 8 VCU
 SG_ Motor4_TqLimHi : 12|12@1+ (0.5,0) [0|2047.5] "N.m" VCU
 SG_ Motor4_TqLimLo : 16|12@1- (0.5,0) [-1024|1023.5] "N.m" VCU
 SG_ Motor4_TqTable : 36|12@1+ (0.5,0) [0|2047.5] "N.m" VCU
 SG_ Motor4_CreepTorque : 40|12@1+ (0.1,0) [0|409.5] "N.m" VCU
 SG_ Motor4_TqLimMultHi : 48|8@1+ (0.005,0) [0|1.275] "frac" VCU
 SG_ Motor4_TqLimMultLo : 56|8@1+ (0.005,0) [0|1.275] "frac" VCU

BO_ 77823982 M134_MotorTorqueData8: 8 VCU
 SG_ Motor4_ReverseTorque : 12|12@1+ (0.1,0) [0|409.5] "N.m" VCU
 SG_ Motor4_TorqueTrimTable : 16|12@1- (0.001,0) [-2.048|2.047] "frac" VCU
 SG_ Launch_Torque_Multiplier : 24|8@1+ (1,0) [0|255] "" VCU
 SG_ Launch_Torque_Time : 32|8@1+ (0.1,0) [0|25.5] "s" VCU

BO_ 77823984 M136_MotorSpeedData1: 8 VCU
 SG_ IdleTarget_Speed : 8|16@1+ (0.25,0) [0|16383.75] "rpm" VCU
 SG_ StartRamp_TargetSpeed : 24|16@1+ (0.25,0) [0|16383.75] "rpm" VCU
 SG_ FreeRevTarget_Speed : 40|16@1+ (0.25,0) [0|16383.75] "rpm" VCU
 SG_ BurnoutTargetSpeed : 56|16@1+ (0.25,0) [0|16383.75] "rpm" VCU

BO_ 77823986 M138_MotorSpeedData2: 8 VCU
 SG_ LaunchTarget_Speed : 8|16@1+ (0.25,0) [0|16383.75] "rpm" VCU
 SG_ Motor_TargetSpeed : 24|16@1+ (0.25,0) [0|16383.75] "rpm" VCU
 SG_ SpeedControl_PID : 44|12@1- (0.5,0) [-1024|1023.5] "N.m" VCU
 SG_ SpeedControl_PID_Error : 48|12@1- (0.5,0) [-1024|1023.5] "N.m" VCU

BO_ 77823988 M140_MotorSpeedData3: 6 VCU
 SG_ SpeedControl_PID_PTerm : 12|12@1- (0.5,0) [-1024|1023.5] "N.m" VCU
 SG_ SpeedControl_PID_ITerm : 16|12@1- (0.5,0) [-1024|1023.5] "N.m" VCU
 SG_ SpeedControl_PID_DTerm : 36|12@1- (0.5,0) [-1024|1023.5] "N.m" VCU

BO_ 77823996 M144_VCU_FaultStates1: 7 VCU
 SG_ Fault_AccPedal2_Spike : 0|1@1+ (1,0) [0|1] "" VCU
 SG_ Fault_AccPedal2_InputLo : 1|1@1+ (1,0) [0|1] "" VCU
 SG_ Fault_AccPedal2_InputHi : 2|1@1+ (1,0) [0|1] "" VCU
 SG_ Fault_AccPedal1_Spike : 3|1@1+ (1,0) [0|1] "" VCU
 SG_ Fault_AccPedal1_Input_Lo : 4|1@1+ (1,0) [0|1] "" VCU
 SG_ Fault_AccPedal1_Input_Hi : 5|1@1+ (1,0) [0|1] "" VCU
 SG_ Fault_Acc_Power : 6|1@1+ (1,0) [0|1] "" VCU
 SG_ Fault_Acc_LED : 7|1@1+ (1,0) [0|1] "" VCU
 SG_ Fault_Cool_Temp1_InputLo : 8|1@1+ (1,0) [0|1] "" VCU
 SG_ Fault_Cool_Temp1_InputHi : 9|1@1+ (1,0) [0|1] "" VCU
 SG_ Fault_Cooling_Pump2 : 10|1@1+ (1,0) [0|1] "" VCU
 SG_ Fault_Cooling_Pump1 : 11|1@1+ (1,0) [0|1] "" VCU
 SG_ Fault_Brk_Press_InputLo : 12|1@1+ (1,0) [0|1] "" VCU
 SG_ Fault_Brk_Press_InputHi : 13|1@1+ (1,0) [0|1] "" VCU
 SG_ Fault_Brake_Lamps : 14|1@1+ (1,0) [0|1] "" VCU
 SG_ Fault_AccelPedal_XCheck : 15|1@1+ (1,0) [0|1] "" VCU
 SG_ Fault_MC1SupplyVoltageLow : 16|1@1+ (1,0) [0|1] "" VCU
 SG_ Fault_MC1_Contactor : 17|1@1+ (1,0) [0|1] "" VCU
 SG_ Fault_IgnChgPlug_XCheck : 18|1@1+ (1,0) [0|1] "" VCU
 SG_ Fault_Idle_Target : 19|1@1+ (1,0) [0|1] "" VCU
 SG_ Fault_Head_Lamps : 20|1@1+ (1,0) [0|1] "" VCU
 SG_ Fault_DCVoltage_SafeLight : 21|1@1+ (1,0) [0|1] "" VCU
 SG_ Fault_Cool_Temp2_InputLo : 22|1@1+ (1,0) [0|1] "" VCU
 SG_ Fault_Cool_Temp2_InputHi : 23|1@1+ (1,0) [0|1] "" VCU
 SG_ Fault_LineLock_Sol : 24|1@1+ (1,0) [0|1] "" VCU
 SG_ Fault_MC5SupplyVoltageLow : 25|1@1+ (1,0) [0|1] "" VCU
 SG_ Fault_MC4SupplyVoltageLow : 26|1@1+ (1,0) [0|1] "" VCU
 SG_ Fault_MC4_Contactor : 27|1@1+ (1,0) [0|1] "" VCU
 SG_ Fault_MC3SupplyVoltageLow : 28|1@1+ (1,0) [0|1] "" VCU
 SG_ Fault_MC3_Contactor : 29|1@1+ (1,0) [0|1] "" VCU
 SG_ Fault_MC2SupplyVoltageLow : 30|1@1+ (1,0) [0|1] "" VCU
 SG_ Fault_MC2_Contactor : 31|1@1+ (1,0) [0|1] "" VCU
 SG_ Fault_Regen_LeverXChk : 32|1@1+ (1,0) [0|1] "" VCU
 SG_ Fault_Park_Lamps : 33|1@1+ (1,0) [0|1] "" VCU
 SG_ Fault_Manual_Regen2_Spike : 34|1@1+ (1,0) [0|1] "" VCU
 SG_ Fault_Manual_Regen2_InputLo : 35|1@1+ (1,0) [0|1] "" VCU
 SG_ Fault_Manual_Regen2_InputHi : 36|1@1+ (1,0) [0|1] "" VCU
 SG_ Fault_Manual_Regen1_Spike : 37|1@1+ (1,0) [0|1] "" VCU
 SG_ Fault_Manual_Regen1_InputLo : 38|1@1+ (1,0) [0|1] "" VCU
 SG_ Fault_Manual_Regen1_InputHi : 39|1@1+ (1,0) [0|1] "" VCU
 SG_ Fault_WheelBar_Press1_InputHi : 40|1@1+ (1,0) [0|1] "" VCU
 SG_ Fault_Trans_Temp_InputLo : 41|1@1+ (1,0) [0|1] "" VCU
 SG_ Fault_Trans_Temp_InputHi : 42|1@1+ (1,0) [0|1] "" VCU
 SG_ Fault_Trans_Press_InputLo : 43|1@1+ (1,0) [0|1] "" VCU
 SG_ Fault_Trans_Press_InputHi : 44|1@1+ (1,0) [0|1] "" VCU
 SG_ Fault_TransBrk_Sol : 45|1@1+ (1,0) [0|1] "" VCU
 SG_ Fault_Shift_Sol : 46|1@1+ (1,0) [0|1] "" VCU
 SG_ Fault_Reverse_Lamps : 47|1@1+ (1,0) [0|1] "" VCU
 SG_ Fault_Wheel_Speed_NR_Spike : 48|1@1+ (1,0) [0|1] "" VCU
 SG_ Fault_Wheel_Speed_NL_Spike : 49|1@1+ (1,0) [0|1] "" VCU
 SG_ Fault_Wheel_Speed_DR_Spike : 50|1@1+ (1,0) [0|1] "" VCU
 SG_ Fault_Wheel_Speed_DL_Spike : 51|1@1+ (1,0) [0|1] "" VCU
 SG_ Fault_Wheel_Speed_DD_Spike : 52|1@1+ (1,0) [0|1] "" VCU
 SG_ Fault_WheelBar_Press2_InputLo : 53|1@1+ (1,0) [0|1] "" VCU
 SG_ Fault_WheelBar_Press2_InputHi : 54|1@1+ (1,0) [0|1] "" VCU
 SG_ Fault_WheelBar_Press1_InputLo : 55|1@1+ (1,0) [0|1] "" VCU
